VERSION "1.3"

CM_ "RVC DBC File
Author: Dominique Parolin & Damiano Liviero
for Winnebago Industries Inc.
";

NS_ :

BS_:
BU_:

BO_ 2382359889 LEVELING_CONTROL_STATUS: 8 Vector__XXX
    SG_ Operating_Mode        :   0|8@1+      (1,0)   [0|255]   "A"     Vector__XXX
    SG_ Auto_Jack_Status        :   8|2@1+      (1,0)   [0|3]     "A"     Vector__XXX
    SG_ Air_Level_Sleep_Mode        :   10|2@1+     (1,0)   [0|3]     "A"     Vector__XXX
    SG_ Air_Releveling_Mode        :   12|2@1+     (1,0)   [0|3]     "A"     Vector__XXX
    SG_ Excessive_Slope_Initial_Warning        :   16|2@1+     (1,0)   [0|3]     "A"     Vector__XXX
    SG_ Excessive_Slope_Final_Warning        :   18|2@1+     (1,0)   [0|3]     "A"     Vector__XXX
    SG_ Leveling_System_Master_Warning        :   20|2@1+     (1,0)   [0|3]     "A"     Vector__XXX
    SG_ Jack_Retrack_Left_Rear        :   24|2@1+     (1,0)   [0|3]     "A"     Vector__XXX
    SG_ Jack_Extend_Left_Rear        :   26|2@1+     (1,0)   [0|3]     "A"     Vector__XXX
    SG_ Jack_Retrack_Right_Front        :   28|2@1+     (1,0)   [0|3]     "A"     Vector__XXX
    SG_ Jack_Extend_Right_Front        :   30|2@1+     (1,0)   [0|3]     "A"     Vector__XXX
    SG_ Jack_Retrack_Right_Rear        :   32|2@1+     (1,0)   [0|3]     "A"     Vector__XXX
    SG_ Jack_Extend_Right_Rear        :   34|2@1+     (1,0)   [0|3]     "A"     Vector__XXX
    SG_ Jack_Retrack_Left_Front        :   36|2@1+     (1,0)   [0|3]     "A"     Vector__XXX
    SG_ Jack_Extend_Left_Front        :   38|2@1+     (1,0)   [0|3]     "A"     Vector__XXX
    SG_ Jack_Retrack_Tongue        :   48|2@1+     (1,0)   [0|3]     "A"     Vector__XXX
    SG_ Jack_Extend_Tongue        :   50|2@1+     (1,0)   [0|3]     "A"     Vector__XXX
    SG_ Park_Brake        :   56|2@1+     (1,0)   [0|3]     "A"     Vector__XXX
    SG_ Ignition_Key        :   58|2@1+     (1,0)   [0|3]     "A"     Vector__XXX
    SG_ Low_Voltage        :   60|2@1+     (1,0)   [0|3]     "A"     Vector__XXX
    SG_ Other_Lockout        :   62|2@1+     (1,0)   [0|3]     "A"     Vector__XXX

    0 "Leveling system may operate"
    1 "Leveling system may not operate because of Park Brake status"
    3 "Unavailable";

    0 "Leveling system may operate"
    1 "Leveling system may not operate because of Ignition status"
    3 "Unavailable";

    0 "Leveling system may operate"
    1 "Leveling system may not operate because of Low Voltage status"
    3 "Unavailable";

    0 "Leveling system may operate"
    1 "Leveling system may not operate because of an additional lockout"
    3 "Unavailable";

    0 "Inactive"
    3 "Store Active"
    72 "Manual Hydraulic leveling - Biax mode"
    82 "Automatic Hydraulic leveling - Biax mode";

BO_ 2180958720 DM_RV: 8 Vector__XXX
    SG_ Operating_Status_1:        0|2@1+      (1,0)   [0|2]   "A"     Vector__XXX
    SG_ Operating_Status_2:        2|2@1+      (1,0)   [0|2]   "A"     Vector__XXX
    SG_ Yellow_Lamp_Status:        4|2@1+      (1,0)   [0|2]   "A"     Vector__XXX
    SG_ Red_Lamp_Status:        6|2@1+      (1,0)   [0|2]   "A"     Vector__XXX
    SG_ DSA:        8|8@1+      (1,0)   [0|255]   "A"     Vector__XXX
    SG_ SPN_MSB:        16|8@1+      (1,0)   [0|255]   "A"     Vector__XXX
    SG_ SPN_ISB:        24|8@1+      (1,0)   [0|255]   "A"     Vector__XXX
    SG_ FMI:        32|5@1+      (1,0)   [0|255]   "A"     Vector__XXX
    SG_ SPN_LSB:        37|3@1+      (1,0)   [0|255]   "A"     Vector__XXX

    0   "Reserved"
    63  "Reserved"
    64  "Generator"
    65  "Genstart Controller"
    66  "Inverter #1"
    67  "Inverter #2"
    68  "Control Panel"
    69  "Battery State of Charge Monitor"
    70  "Battery"

    73  "LPG Tank System"

    77  "AC Load Monitor / Controller"

    81  "Hydraulic/Electric Leveling System Controller"

    88  "Main Thermostat"

    94  "Main Furnace (Conventional)"

    101 "Water Heater #1"
    102 "Water Heater #2"
    103 "Air Conditioner #1"
    104 "Air Conditioner #2"
    105 "Air Conditioner #3"
    106 "Air Conditioner #4"

    132 "DC Input, Keypad"

    141 "Solar Charge Controller"
    142 "Roof Fan"

    144 "Generic Alarm"

    249 "Service Tool"
    250 "System Clock"

    252 "Chassis Bridge"

    255 "Data Invalid";

    0	"Datum value above normal range"
    1	"Datum value below normal range"
    2	"Datum value erratic or invalid"
    3	"Short circuit to high voltage (or complete sensor input failure)"
    4	"Short circuit to low voltage (or complete sensor input failure) "
    5	"Open circuit, or output current below normal"
    6	"Grounded circuit, or output current above normal"
    7	"Mechanical device not responding"
    8	"Datum value showing error of frequency, pulse width, or period"
    9	"Datum not updating at proper rate"
    10	"Datum value fluctuating at abnormal rate"
    11	"Failure not identifiable"
    12	"Bad intelligent RV-C node"
    13	"Calibration required"
    14	"None of the above"
    15	"Datum valid but above normal operational range (least severe) "
    16	"Datum valid but above normal operational range (moderately severe) "
    17	"Datum valid but below normal operational range (least severe) "
    18	"Datum valid but below normal operational range (moderately severe) "
    19	"Received invalid network datum "
    20	"Network Device Not Responding "
    21	"Networked Device Not Responding (failure due to the unresponsiveness of a second networked device) "
    22	"Reverse polarity "
    23	"Reserved"
    24	"Reserved"
    25	"Reserved"
    26	"Reserved"
    27	"Reserved"
    28	"Reserved"
    29	"Reserved"
    30	"Reserved"
    31	"Failure mode not available";

    0 "Specific Point Unknown"
    1 "Node Microprocessor (or ECM)"
    2 "Node Analog-Digital Converter"
    3 "Node Settings or Configuration"
    4 "Node RAM"
    5 "Node Power Supply"
    6 "Node Temperature"
    7 "Node Clock / Timer"
    8 "Node Date / Time. Usually indicates a product that requires a clock DGN from another source."
    9 "Node RV-C Connection. Usually indicates a product that requires a specific DGN from another source."
    10 "Node Serial/ID Number"
    11 "Node Processor Supervisor (Watchdog)"
    12 "Node Firmware"
    13 "Node Internal Subnetwork Communications.";

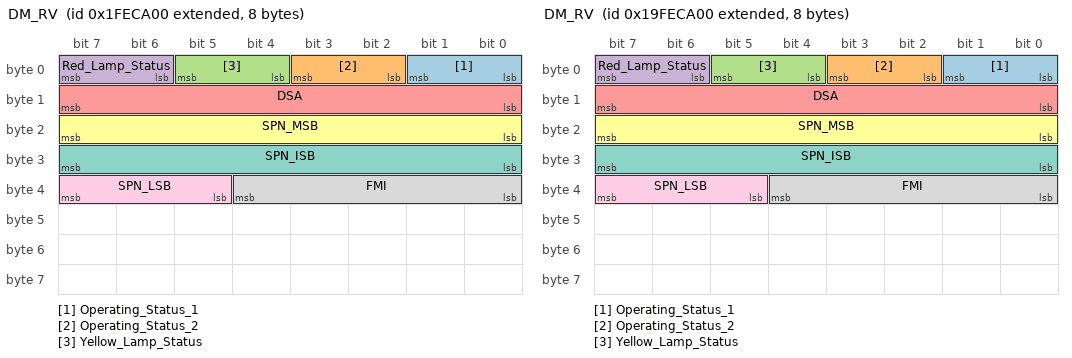
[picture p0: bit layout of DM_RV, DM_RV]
BO_ 2583611904 DM_RV: 8 Vector__XXX
    SG_ Operating_Status_1:        0|2@1+      (1,0)   [0|2]   "A"     Vector__XXX
    SG_ Operating_Status_2:        2|2@1+      (1,0)   [0|2]   "A"     Vector__XXX
    SG_ Yellow_Lamp_Status:        4|2@1+      (1,0)   [0|2]   "A"     Vector__XXX
    SG_ Red_Lamp_Status:        6|2@1+      (1,0)   [0|2]   "A"     Vector__XXX
    SG_ DSA:        8|8@1+      (1,0)   [0|255]   "A"     Vector__XXX
    SG_ SPN_MSB:        16|8@1+      (1,0)   [0|255]   "A"     Vector__XXX
    SG_ SPN_ISB:        24|8@1+      (1,0)   [0|255]   "A"     Vector__XXX
    SG_ FMI:        32|5@1+      (1,0)   [0|255]   "A"     Vector__XXX
    SG_ SPN_LSB:        37|3@1+      (1,0)   [0|255]   "A"     Vector__XXX

    0   "Reserved"
    63  "Reserved"
    64  "Generator"
    65  "Genstart Controller"
    66  "Inverter #1"
    67  "Inverter #2"
    68  "Control Panel"
    69  "Battery State of Charge Monitor"
    70  "Battery"

    73  "LPG Tank System"

    77  "AC Load Monitor / Controller"

    81  "Hydraulic/Electric Leveling System Controller"

    88  "Main Thermostat"

    94  "Main Furnace (Conventional)"

    101 "Water Heater #1"
    102 "Water Heater #2"
    103 "Air Conditioner #1"
    104 "Air Conditioner #2"
    105 "Air Conditioner #3"
    106 "Air Conditioner #4"

    132 "DC Input, Keypad"

    141 "Solar Charge Controller"
    142 "Roof Fan"

    144 "Generic Alarm"

    249 "Service Tool"
    250 "System Clock"

    252 "Chassis Bridge"

    255 "Data Invalid";

    0	"Datum value above normal range"
    1	"Datum value below normal range"
    2	"Datum value erratic or invalid"
    3	"Short circuit to high voltage (or complete sensor input failure)"
    4	"Short circuit to low voltage (or complete sensor input failure) "
    5	"Open circuit, or output current below normal"
    6	"Grounded circuit, or output current above normal"
    7	"Mechanical device not responding"
    8	"Datum value showing error of frequency, pulse width, or period"
    9	"Datum not updating at proper rate"
    10	"Datum value fluctuating at abnormal rate"
    11	"Failure not identifiable"
    12	"Bad intelligent RV-C node"
    13	"Calibration required"
    14	"None of the above"
    15	"Datum valid but above normal operational range (least severe) "
    16	"Datum valid but above normal operational range (moderately severe) "
    17	"Datum valid but below normal operational range (least severe) "
    18	"Datum valid but below normal operational range (moderately severe) "
    19	"Received invalid network datum "
    20	"Network Device Not Responding "
    21	"Networked Device Not Responding (failure due to the unresponsiveness of a second networked device) "
    22	"Reverse polarity "
    23	"Reserved"
    24	"Reserved"
    25	"Reserved"
    26	"Reserved"
    27	"Reserved"
    28	"Reserved"
    29	"Reserved"
    30	"Reserved"
    31	"Failure mode not available";

    0 "Specific Point Unknown"
    1 "Node Microprocessor (or ECM)"
    2 "Node Analog-Digital Converter"
    3 "Node Settings or Configuration"
    4 "Node RAM"
    5 "Node Power Supply"
    6 "Node Temperature"
    7 "Node Clock / Timer"
    8 "Node Date / Time. Usually indicates a product that requires a clock DGN from another source."
    9 "Node RV-C Connection. Usually indicates a product that requires a specific DGN from another source."
    10 "Node Serial/ID Number"
    11 "Node Processor Supervisor (Watchdog)"
    12 "Node Firmware"
    13 "Node Internal Subnetwork Communications.";

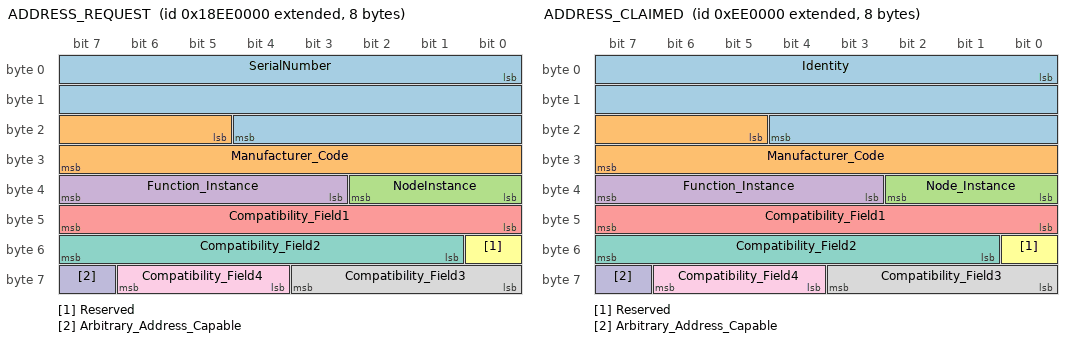
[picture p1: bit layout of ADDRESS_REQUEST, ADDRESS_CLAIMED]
BO_ 2565734400 ADDRESS_REQUEST: 8 Vector__XXX
    SG_ SerialNumber:        0|21@1+      (1,0)   [0|2097151]     "A"     Vector__XXX
    SG_ Manufacturer_Code:        21|11@1+     (1,0)   [0|100000]      "A"     Vector__XXX
    SG_ NodeInstance:        32|3@1+ (1,0) [0|7] "A" Vector__XXX
    SG_ Function_Instance:        35|5@1+ (1,0) [0|31] "A" Vector__XXX
    SG_ Compatibility_Field1:        40|8@1+ (1,0) [0|255] "A" Vector__XXX
    SG_ Reserved:        48|1@1+ (1,0) [0|1] "A" Vector__XXX
    SG_ Compatibility_Field2:        49|7@1+ (1,0) [0|127] "A" Vector__XXX
    SG_ Compatibility_Field3:        56|4@1+ (1,0) [0|15] "A" Vector__XXX
    SG_ Compatibility_Field4:        60|3@1+ (1,0) [0|7] "A" Vector__XXX
    SG_ Arbitrary_Address_Capable:        63|1@1+ (1,0) [0|1] "A" Vector__XXX

    0 "Node uses a fixed source address"
    1 "Node supports address claiming";

    101	"Atwood Mobile Products"
    102	"Carefree of Colorado"
    103	"Dometic Corporation"
    104	"Freightliner Custom Chassis Corp."
    105	"General Dynamics - Intellitec Products"
    106	"Girard Systems"
    107	"Hopkins Manufacturing Corp."
    108	"HWH Corporation"
    109	"Integrated Power Systems"
    110	"Onan / Cummins Power Generation"
    111	"Progressive Dynamics, Inc."
    112	"SilverLeaf Electronics, Inc."
    113	"Spartan Motors Chassis, Inc."
    114	"Technology Research Corporation"
    115	"Transportation Systems Design, Inc."
    116	"Vehicle Systems, Inc."
    117	"Wire Design, Inc."
    118	"Workhorse Custom Chassis"
    119	"Xantrex Technology, Inc."
    120	"Power Gear"
    121	"RV Products"
    122	"Suburban"
    123	"Borg-Warner"
    124	"Garnet Instruments"
    125	"American Technology"
    126	"Automated Engineering Corp.";

BO_ 2163081216 ADDRESS_CLAIMED: 8 Vector__XXX
    SG_ Identity:        0|21@1+      (1,0)   [0|2097151]     "A"     Vector__XXX
    SG_ Manufacturer_Code:        21|11@1+     (1,0)   [0|100000]      "A"     Vector__XXX
    SG_ Node_Instance:        32|3@1+ (1,0) [0|7] "A" Vector__XXX
    SG_ Function_Instance:        35|5@1+ (1,0) [0|31] "A" Vector__XXX
    SG_ Compatibility_Field1:        40|8@1+ (1,0) [0|255] "A" Vector__XXX
    SG_ Reserved:        48|1@1+ (1,0) [0|1] "A" Vector__XXX
    SG_ Compatibility_Field2:        49|7@1+ (1,0) [0|127] "A" Vector__XXX
    SG_ Compatibility_Field3:        56|4@1+ (1,0) [0|15] "A" Vector__XXX
    SG_ Compatibility_Field4:        60|3@1+ (1,0) [0|7] "A" Vector__XXX
    SG_ Arbitrary_Address_Capable:        63|1@1+ (1,0) [0|1] "A" Vector__XXX

    0 "Node uses a fixed source address"
    1 "Node supports address claiming";

    101	"Atwood Mobile Products"
    102	"Carefree of Colorado"
    103	"Dometic Corporation"
    104	"Freightliner Custom Chassis Corp."
    105	"General Dynamics - Intellitec Products"
    106	"Girard Systems"
    107	"Hopkins Manufacturing Corp."
    108	"HWH Corporation"
    109	"Integrated Power Systems"
    110	"Onan / Cummins Power Generation"
    111	"Progressive Dynamics, Inc."
    112	"SilverLeaf Electronics, Inc."
    113	"Spartan Motors Chassis, Inc."
    114	"Technology Research Corporation"
    115	"Transportation Systems Design, Inc."
    116	"Vehicle Systems, Inc."
    117	"Wire Design, Inc."
    118	"Workhorse Custom Chassis"
    119	"Xantrex Technology, Inc."
    120	"Power Gear"
    121	"RV Products"
    122	"Suburban"
    123	"Borg-Warner"
    124	"Garnet Instruments"
    125	"American Technology"
    126	"Automated Engineering Corp.";

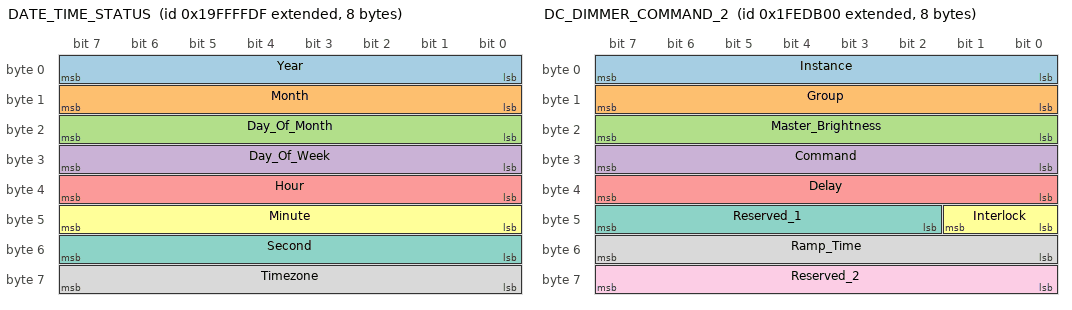
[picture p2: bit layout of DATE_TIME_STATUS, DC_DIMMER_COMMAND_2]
BO_ 2583691231 DATE_TIME_STATUS: 8 Vector__XXX
    SG_ Year:        0|8@1+  (1,2000)   [0|250]     "Year"  Vector__XXX
    SG_ Month:        8|8@1+  (1,0)   [1|12]     "Month"  Vector__XXX
    SG_ Day_Of_Month:        16|8@1+    (1,0)    [0|31]   "Day Number"     Vector__XXX
    SG_ Day_Of_Week:        24|8@1+    (1,0)   [1|7]   "Day Name"     Vector__XXX
    SG_ Hour:        32|8@1+    (1,0)   [0|23]   "h"     Vector__XXX
    SG_ Minute:        40|8@1+    (1,0)   [0|59]   "min"     Vector__XXX
    SG_ Second:        48|8@1+    (1,0)   [0|59]   "s"     Vector__XXX
    SG_ Timezone:        56|8@1+    (1,0)   [0|255]   "h"     Vector__XXX

    0 "Invalid"
    1 "Sunday"
    2 "Monday"
    3 "Tuesday"
    4 "Wednesday"
    5 "Thursday"
    6 "Friday"
    7 "Saturday"
    255 "Not supported";

    0 "Greenwich Mean Time"
    4 "Eastern Daylight Time"
    5 "Eastern Standard Time"
    7 "Pacific Daylight Time"
    8 "Pacific Standard Time"
    0 "Western European Time"
    22 "Central European Summer Time"
    255 "Not supported";

BO_ 2583615167 MFG_SPECIFIC_CLAIM_REQUEST: 8 Vector__XXX
    SG_ Manufacturer_Code_MSB:        0|16@1+     (1,0)   [0|100000]      "A"     Vector__XXX

    101	"Atwood Mobile Products"
    102	"Carefree of Colorado"
    103	"Dometic Corporation"
    104	"Freightliner Custom Chassis Corp."
    105	"General Dynamics - Intellitec Products"
    106	"Girard Systems"
    107	"Hopkins Manufacturing Corp."
    108	"HWH Corporation"
    109	"Integrated Power Systems"
    110	"Onan / Cummins Power Generation"
    111	"Progressive Dynamics, Inc."
    112	"SilverLeaf Electronics, Inc."
    113	"Spartan Motors Chassis, Inc."
    114	"Technology Research Corporation"
    115	"Transportation Systems Design, Inc."
    116	"Vehicle Systems, Inc."
    117	"Wire Design, Inc."
    118	"Workhorse Custom Chassis"
    119	"Xantrex Technology, Inc."
    120	"Power Gear"
    121	"RV Products"
    122	"Suburban"
    123	"Borg-Warner"
    124	"Garnet Instruments"
    125	"American Technology"
    126	"Automated Engineering Corp.";

BO_ 2180963072 DC_DIMMER_COMMAND_2: 8 Vector__XXX
    SG_ Instance:        0|8@1+ (1,0) [1|255] "Instance" Vector__XXX
    SG_ Group:        8|8@1+ (1,0) [129|255] "Group" Vector__XXX
    SG_ Master_Brightness:        16|8@1+ (0.5,0) [0|200] "%" Vector__XXX
    SG_ Command:        24|8@1+ (1,0) [0|255] "Cmd" Vector__XXX
    SG_ Delay:        32|8@1+ (1,0) [0|255] "Sec/Min" Vector__XXX
    SG_ Interlock:        40|2@1+ (1,0) [0|255] "" Vector__XXX
    SG_ Reserved_1:        42|6@1+ (1,0) [0|255] "" Vector__XXX
    SG_ Ramp_Time:        48|8@1+ (1,0) [0|255] "" Vector__XXX
    SG_ Reserved_2:        56|8@1+ (1,0) [0|255] "" Vector__XXX

    255 "Group Command";

    129 "Node Group 1"
    130 "Node Group 2"
    131 "Node Group 3"
    132 "Node Group 4"
    133 "Node Group 5"
    134 "Node Group 6"
    135 "Node Group 7"
    136 "Node Group 8"
    255 "Non-group command";

    230 "Scene 1 Memory Value"
    231 "Scene 2 Memory Value"
    232 "Scene 3 Memory Value"
    233 "Scene 4 Memory Value"
    234 "Scene 5 Memory Value"
    235 "Scene 6 Memory Value"
    236 "Scene 7 Memory Value"
    237 "Scene 8 Memory Value"
    238 "Scene 9 Memory Value"
    239 "Scene 10 Memory Value"
    240 "Scene 11 Memory Value"
    249 "Scene 20 Memory Value"
    250 "selects the Dimmed Memory Value"
    251 "selects the Master Memory Value";

CM_" Need to update stuff below for RVC";

    0 "Set Level Direct"
    1 "ON - 100% direct"
    2 "ON - Delay"
    3 "OFF"
    4 "Stop Ramping"
    5 "Toggle between 0% and 100% and vice versa"

    8 "Switch Poke"
    9 "Switch Press and hold"
    10 "Switch Release"

    19 "Ramp Up from current brightness to 100%"
    20 "Ramp down from current brightness to 0%";

    241 "5 min"
    242 "6 min"
    243 "7 min"
    244 "8 min"
    245 "9 min"
    246 "10 min"
    247 "11 min"
    248 "12 min"
    249 "13 min"
    250 "14 min"
    255 "Continuous/NA";

    0 "No interlock active"
    1 "Interlock A"
    2 "Interlock B"
    3 "NA";

    63 "NA";

    255 "NA";

    255 "NA";

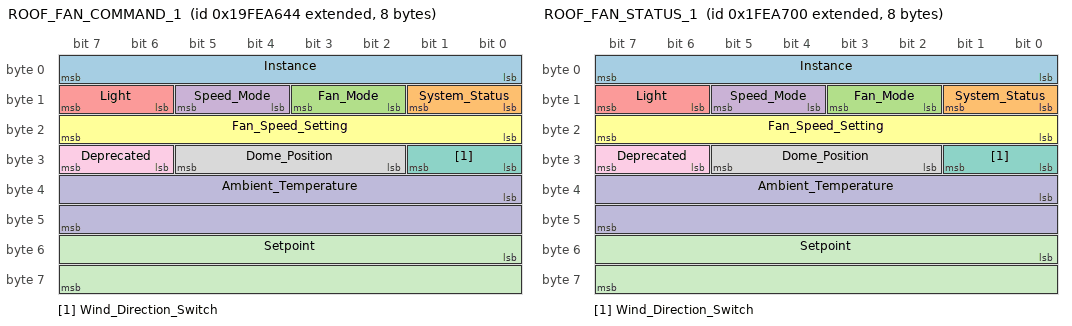
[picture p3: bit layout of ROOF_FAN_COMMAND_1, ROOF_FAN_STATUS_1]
BO_ 2583602756 ROOF_FAN_COMMAND_1: 8   Vector__XXX
    SG_ Instance:        0|8@1+ (1,0) [0|255] "Instance" Vector__XXX
    SG_ System_Status:        8|2@1+  (1,0)   [0|15]  "onOff"  Vector__XXX
    SG_ Fan_Mode:        10|2@1+ (1,0)   [0|3]   "Mode"  Vector__XXX
    SG_ Speed_Mode:        12|2@1+ (1,0)   [0|3]   "Mode"  Vector__XXX
    SG_ Light:        14|2@1+ (1,0)   [0|1]   "onOff" Vector__XXX
    SG_ Fan_Speed_Setting:        16|8@1+ (0.5,0)   [0|255] "%" Vector__XXX
    SG_ Wind_Direction_Switch:        24|2@1+ (1,0)   [0|3]   ""  Vector__XXX
    SG_ Dome_Position:        26|4@1+ (1,0)   [0|15]  ""  Vector__XXX
    SG_ Deprecated:        30|2@1+ (1,0)   [0|15]  ""  Vector__XXX
    SG_ Ambient_Temperature:        32|16@1+    (0.03125,-273) [-273|1735] "deg C" Vector__XXX
    SG_ Setpoint:        48|16@1+    (0.03125,-273) [-273|1735] "deg C" Vector__XXX

    0 "Off"
    1 "On";

    0 "Auto"
    1 "Forced On";

    0 "Auto (Variable)"
    1 "Manual";

    0 "Off"
    1 "On";

    0 "Air Out"
    1 "Air In";

    0 "Closed"
    1 "1/4 Open"
    2 "1/2 Open"
    3 "3/4 Open"
    4 "Open";

BO_ 2180949760 ROOF_FAN_STATUS_1: 8   Vector__XXX
    SG_ Instance:        0|8@1+ (1,0) [0|255] "Instance" Vector__XXX
    SG_ System_Status:        8|2@1+  (1,0)   [0|15]  "onOff"  Vector__XXX
    SG_ Fan_Mode:        10|2@1+ (1,0)   [0|3]   "Mode"  Vector__XXX
    SG_ Speed_Mode:        12|2@1+ (1,0)   [0|3]   "Mode"  Vector__XXX
    SG_ Light:        14|2@1+ (1,0)   [0|1]   "onOff" Vector__XXX
    SG_ Fan_Speed_Setting:        16|8@1+ (0.5,0)   [0|255] "%" Vector__XXX
    SG_ Wind_Direction_Switch:        24|2@1+ (1,0)   [0|3]   ""  Vector__XXX
    SG_ Dome_Position:        26|4@1+ (1,0)   [0|15]  ""  Vector__XXX
    SG_ Deprecated:        30|2@1+ (1,0)   [0|15]  ""  Vector__XXX
    SG_ Ambient_Temperature:        32|16@1+    (0.03125,-273) [-273|1735] "deg C" Vector__XXX
    SG_ Setpoint:        48|16@1+    (0.03125,-273) [-273|1735] "deg C" Vector__XXX

    0 "Off"
    1 "On";

    0 "Auto"
    1 "Forced On";

    0 "Auto (Variable)"
    1 "Manual";

    0 "Off"
    1 "On";

    0 "Air Out"
    1 "Air In";

    0 "Closed"
    1 "1/4 Open"
    2 "1/2 Open"
    3 "3/4 Open"
    4 "Open";

CM_ "1FF9C";
BO_ 2181012480 THERMOSTAT_AMBIENT_STATUS: 8  Vector__XXX
    SG_ Instance:        0|8@1+  (1,0)   [0|255] ""    Vector__XXX
    SG_ Ambient_Temp:        8|16@1+  (0.03125,-273) [-8736|56799] "deg C"    Vector__XXX

    65535 "Data Invalid";

CM_ "1FEF7";
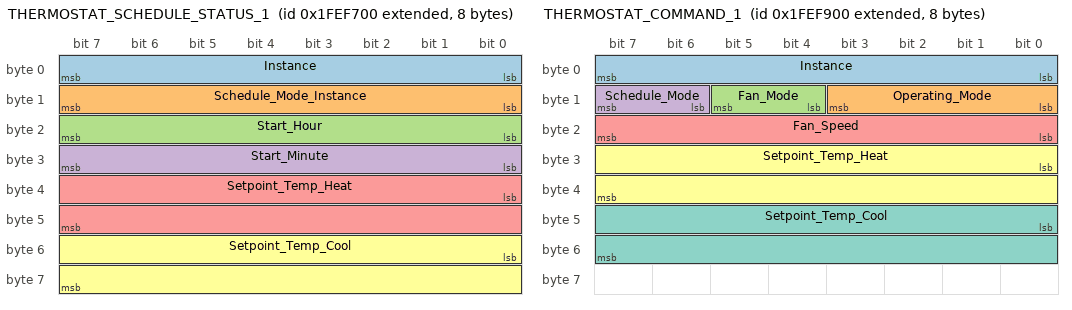
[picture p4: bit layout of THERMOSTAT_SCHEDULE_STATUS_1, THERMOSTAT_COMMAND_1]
BO_ 2180970240 THERMOSTAT_SCHEDULE_STATUS_1: 8  Vector__XXX
    SG_ Instance:        0|8@1+  (1,0)   [0|255] ""    Vector__XXX
    SG_ Schedule_Mode_Instance:        8|8@1+  (1,0)   [0|255] ""    Vector__XXX
    SG_ Start_Hour:        16|8@1+  (1,0)   [0|255] "hr"    Vector__XXX
    SG_ Start_Minute:        24|8@1+  (1,0)   [0|255] "min"    Vector__XXX
    SG_ Setpoint_Temp_Heat:        32|16@1+  (0.03125,-273) [-8736|56799] "deg C"    Vector__XXX
    SG_ Setpoint_Temp_Cool:        48|16@1+  (0.03125,-273) [-8736|56799] "deg C"    Vector__XXX

    0 "Sleep"
    1 "Wake"
    2 "Away"
    3 "Return"
    250 "Storage"
    255 "Data invalid";

    0 "12:00 AM"
    12 "12:00 Noon"
    23 "11:00 PM"
    255 "Data invalid";

CM_ "1FEF9";
BO_ 2180970752 THERMOSTAT_COMMAND_1: 8  Vector__XXX
    SG_ Instance:        0|8@1+  (1,0)   [0|255] ""    Vector__XXX
    SG_ Operating_Mode:        8|4@1+  (1,0)   [0|15] ""    Vector__XXX
    SG_ Fan_Mode:        12|2@1+  (1,0)   [0|3] ""    Vector__XXX
    SG_ Schedule_Mode:        14|2@1+  (1,0)   [0|3] ""    Vector__XXX
    SG_ Fan_Speed:        16|8@1+  (0.5,0)   [0|255] "%"    Vector__XXX
    SG_ Setpoint_Temp_Heat:        24|16@1+  (0.03125,-273) [-8736|56799] "deg C"    Vector__XXX
    SG_ Setpoint_Temp_Cool:        40|16@1+  (0.03125,-273) [-8736|56799] "deg C"    Vector__XXX

    0 "Off"
    1 "Cool"
    2 "Heat"
    3 "Auto Heat/Cool"
    4 "Fan Only"
    5 "Aux Heat"
    15 "No Data";

    0 "Auto"
    1 "On"
    3 "No Data";

    0 "Disabled"
    1 "Enabled"
    3 "No Data";

    65535 "No Data";

    65535 "No Data";

CM_ "1FFE2";
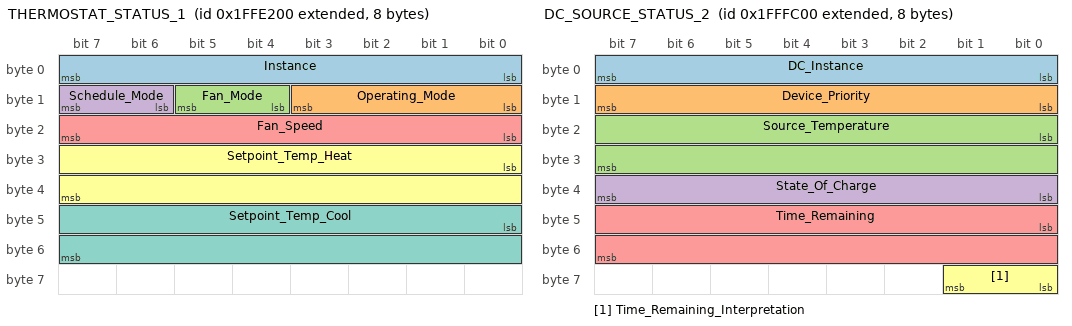
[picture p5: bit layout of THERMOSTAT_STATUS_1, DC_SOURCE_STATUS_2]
BO_ 2181030400 THERMOSTAT_STATUS_1: 8  Vector__XXX
    SG_ Instance:        0|8@1+  (1,0)   [0|255] ""    Vector__XXX
    SG_ Operating_Mode:        8|4@1+  (1,0)   [0|15] ""    Vector__XXX
    SG_ Fan_Mode:        12|2@1+  (1,0)   [0|3] ""    Vector__XXX
    SG_ Schedule_Mode:        14|2@1+  (1,0)   [0|3] ""    Vector__XXX
    SG_ Fan_Speed:        16|8@1+  (0.5,0)   [0|255] "%"    Vector__XXX
    SG_ Setpoint_Temp_Heat:        24|16@1+  (0.03125,-273) [-8736|56799] "deg C"    Vector__XXX
    SG_ Setpoint_Temp_Cool:        40|16@1+  (0.03125,-273) [-8736|56799] "deg C"    Vector__XXX

    0 "Off"
    1 "Cool"
    2 "Heat"
    3 "Auto heat/Cool"
    4 "Fan only"
    5 "Aux Heat"
    15 "Data invalid";

    0 "Auto"
    1 "On"
    3 "Data invalid";

    0 "Disabled"
    1 "Enabled"
    3 "Data invalid";

CM_ "1FEFA";
BO_ 2180971008 THERMOSTAT_STATUS_2: 8  Vector__XXX
    SG_ Instance:        0|8@1+  (1,0)   [0|255] ""    Vector__XXX
    SG_ Current_Schedule_Instance:        8|8@1+  (1,0)   [0|255] ""    Vector__XXX
    SG_ Number_Of_Schedule_Instances:        16|8@1+  (1,0)   [0|255] ""    Vector__XXX

BO_ 2181019392  TANK_STATUS: 8  Vector__XXX
    SG_ Instance:        0|8@1+  (1,0)   [0|255] "Instance"  Vector__XXX
    SG_ Relative_Level:        8|8@1+  (1,0)   [0|255] "Level" Vector__XXX
    SG_ Resolution:        16|8@1+ (1,0)   [0|255] "Resolution"    Vector__XXX
    SG_ Absolute_Level:        24|16@1+    (1,0)   [0|65530]   "Liter" Vector__XXX
    SG_ Tank_Size:        40|16@1+    (1,0)   [0|65530]   "Liter" Vector__XXX

    0 "Fresh Water"
    1 "Black Waste"
    2 "Grey Waste"
    3 "LPG"
    16 "Second Fresh Water"
    17 "Second Black Waste"
    18 "Second Grey Waste"
    19 "Second LPG";

CM_ "Inverter Start";
CM_ "1FFFD";
BO_ 2181037312 DC_SOURCE_STATUS_1: 8 Vector__XXX
    SG_ Instance:        0|8@1+  (1,0)   [0|255]     ""  Vector__XXX
    SG_ Device_Priority:        8|8@1+  (1,0)   [0|255]     ""  Vector__XXX
    SG_ DC_Voltage:        16|16@1+    (0.05,0)    [0|65535]   "V"     Vector__XXX
    SG_ DC_Current:        32|32@1+    (0.001,-2000000)   [-2000000000|2294967295]   "A"     Vector__XXX

    0 "Invalid"
    1 "Main House Battery Bank"
    2 "Chassis Start Battery"
    3 "Secondary House Battery Bank"
    4 "Generator Starter Battery"
    5 "Arbitrary";

    120 "Battery SOC/BMS device"
    100 "Inverter/Charger"
    80 "Charger"
    60 "Inverter"
    40 "Voltmeter/Ammeter"
    20 "Voltmeter"
    0 "No priority, always reporting";

    65535 "Data Invalid";

    4294967295 "Data Invalid";

CM_ "1FFFC";
BO_ 2181037056 DC_SOURCE_STATUS_2: 8 Vector__XXX
    SG_ DC_Instance:        0|8@1+  (1,0)   [0|255]     ""  Vector__XXX
    SG_ Device_Priority:        8|8@1+  (1,0)   [0|255]     ""  Vector__XXX
    SG_ Source_Temperature:        16|16@1+  (0.03125,-273) [-8736|56799] "deg C"    Vector__XXX
    SG_ State_Of_Charge:        32|8@1+    (0.5,0)   [0|255]   "%"     Vector__XXX
    SG_ Time_Remaining:        40|16@1+    (1,0)   [0|65535]   "Min"     Vector__XXX
    SG_ Time_Remaining_Interpretation:        56|2@1+     (1,0)   [0|3]   ""    Vector__XXX

    0 "Invalid"
    1 "Main House Battery Bank"
    2 "Chassis Start Battery"
    3 "Secondary House Battery Bank"
    4 "Generator Starter Battery"
    5 "Arbitrary"
    255 "Data Invalid";

    120 "Battery SOC/BMS device"
    100 "Inverter/Charger"
    80 "Charger"
    60 "Inverter"
    40 "Voltmeter/Ammeter"
    20 "Voltmeter"
    0 "No priority, always reporting";

    65535 "Data Invalid";

    65535 "Data Invalid";

    0 "Time to Empty"
    1 "Time to Full"
    3 "NA - Implicit time to empty";

CM_ "1FFFB";
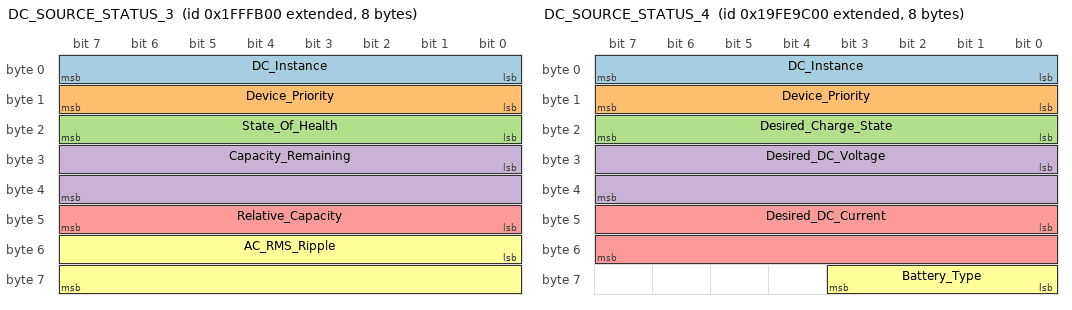
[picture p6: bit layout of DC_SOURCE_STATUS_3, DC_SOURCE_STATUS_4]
BO_ 2181036800 DC_SOURCE_STATUS_3: 8 Vector__XXX
    SG_ DC_Instance:        0|8@1+      (1,0)   [0|255]     ""      Vector__XXX
    SG_ Device_Priority:        8|8@1+      (1,0)   [0|255]     ""      Vector__XXX
    SG_ State_Of_Health:        16|8@1+     (1,0)   [0|255]     "%"     Vector__XXX
    SG_ Capacity_Remaining:        24|16@1+    (1,0)   [0|65530]   "AH"    Vector__XXX
    SG_ Relative_Capacity:        40|8@1+     (1,0)   [0|255]     "%"     Vector__XXX
    SG_ AC_RMS_Ripple:        48|16@1+    (1,0)   [0|65535]   "mV"    Vector__XXX

    0 "Invalid"
    1 "Main House Battery Bank"
    2 "Chassis Start Battery"
    3 "Secondary House Battery Bank"
    4 "Generator Starter Battery"
    5 "Arbitrary"
    255 "Data Invalid";

    120 "Battery SOC/BMS device"
    100 "Inverter/Charger"
    80 "Charger"
    60 "Inverter"
    40 "Voltmeter/Ammeter"
    20 "Voltmeter"
    0 "No priority, always reporting";

    65535 "Data Invalid";

    65535 "Data Invalid";

CM_ "1FE9C";
BO_ 2583600128 DC_SOURCE_STATUS_4: 8 Vector__XXX
    SG_ DC_Instance:                0|8@1+  (1,0)   [0|255]     ""  Vector__XXX
    SG_ Device_Priority:            8|8@1+  (1,0)   [0|255]     ""  Vector__XXX
    SG_ Desired_Charge_State:       16|8@1+  (0.03125,-273) [-8736|56799] "deg C"    Vector__XXX
    SG_ Desired_DC_Voltage:         24|16@1+    (0.5,0)   [0|255]   "%"     Vector__XXX
    SG_ Desired_DC_Current:         40|16@1+    (1,0)   [0|65535]   "Min"     Vector__XXX
    SG_ Battery_Type:               56|4@1+     (1,0)   [0|15]   ""    Vector__XXX

    0 "Invalid"
    1 "Main House Battery Bank"
    2 "Chassis Start Battery"
    3 "Secondary House Battery Bank"
    4 "Generator Starter Battery"
    5 "Arbitrary"
    255 "Data Invalid";

    120 "Battery SOC/BMS device"
    100 "Inverter/Charger"
    80 "Charger"
    60 "Inverter"
    40 "Voltmeter/Ammeter"
    20 "Voltmeter"
    0 "No priority, always reporting";

    0 "Flooded"
    1 "Gel"
    2 "AGM"
    3 "LFP"
    255 "Data Invalid";

CM_ "1FEA5";
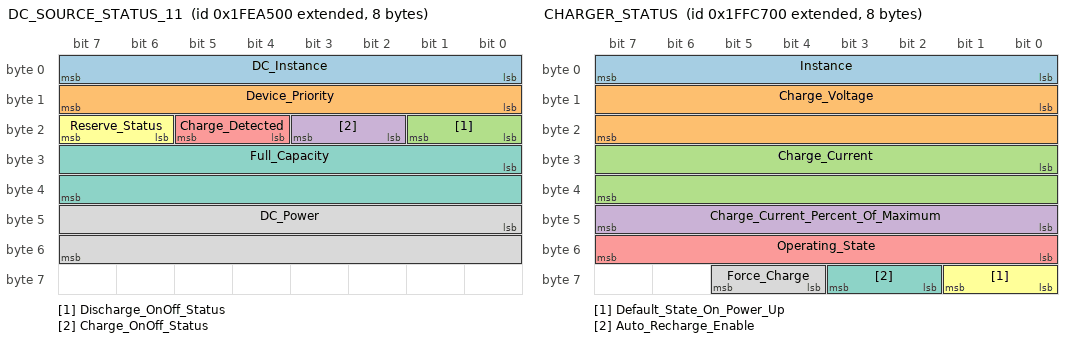
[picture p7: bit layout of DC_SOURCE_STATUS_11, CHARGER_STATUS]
BO_ 2180949248 DC_SOURCE_STATUS_11: 8 Vector__XXX
    SG_ DC_Instance:        0|8@1+      (1,0)   [0|255]     ""      Vector__XXX
    SG_ Device_Priority:        8|8@1+      (1,0)   [0|255]     ""      Vector__XXX
    SG_ Discharge_OnOff_Status:        16|2@1+     (1,0)   [0|255]     ""     Vector__XXX
    SG_ Charge_OnOff_Status:        18|2@1+     (1,0)   [0|255]     ""     Vector__XXX
    SG_ Charge_Detected:        20|2@1+     (1,0)   [0|255]     ""     Vector__XXX
    SG_ Reserve_Status:        22|2@1+     (1,0)   [0|255]     ""     Vector__XXX
    SG_ Full_Capacity:        24|16@1+    (1,0)   [0|65535]   "AH"    Vector__XXX
    SG_ DC_Power:        40|16@1+     (1,0)   [0|65535]  "W"     Vector__XXX

    0 "Invalid"
    1 "Main House Battery Bank"
    2 "Chassis Start Battery"
    3 "Secondary House Battery Bank"
    4 "Generator Starter Battery"
    5 "Arbitrary"
    255 "Data Invalid";

    120 "Battery SOC/BMS device"
    100 "Inverter/Charger"
    80 "Charger"
    60 "Inverter"
    40 "Voltmeter/Ammeter"
    20 "Voltmeter"
    0 "No priority, always reporting";

    65535 "Data Invalid";

    65535 "Data Invalid";

CM_ "1FFD7";
BO_ 2181027584 INVERTER_AC_STATUS_1: 8 Vector__XXX
    SG_ Instance:        0|8@1+  (1,0)   [0|255]     ""  Vector__XXX
    SG_ RMS_Voltage:        8|16@1+  (0.05,0)   [0|65535]     "V"  Vector__XXX
    SG_ RMS_Current:        24|16@1+    (0.05,-1600)   [-32000|33535]   "A"     Vector__XXX
    SG_ Frequency:        40|16@1+    (0.0078125,0)   [0|65535]   "Hz"     Vector__XXX

    65535 "Data Invalid";

    65535 "Data Invalid";

    65535 "Data Invalid";

CM_ "1FFCA";
BO_ 2181024256 CHARGER_AC_STATUS_1: 8 Vector__XXX
    SG_ Instance:        0|8@1+  (1,0)   [0|255]     ""  Vector__XXX
    SG_ RMS_Voltage:        8|16@1+  (0.05,0)   [0|65535]     "V"  Vector__XXX
    SG_ RMS_Current:        24|16@1+    (0.05,-1600)   [-32000|33535]   "A"     Vector__XXX
    SG_ Frequency:        40|16@1+    (0.0078125,0)   [0|65535]   "Hz"     Vector__XXX

    65535 "Data Invalid";

    65535 "Data Invalid";

    65535 "Data Invalid";

CM_ "1FFC9";
BO_ 2181024000 CHARGER_AC_STATUS_2: 8 Vector__XXX
    SG_ Instance:        0|8@1+  (1,0)   [0|255]     ""  Vector__XXX
    SG_ Peak_Voltage:        8|16@1+  (0.05,0)   [0|65535]     "V"  Vector__XXX
    SG_ Peak_Current:        24|16@1+    (0.05,-1600)   [-32000|33535]   "A"     Vector__XXX
    SG_ Ground_Current:        40|16@1+    (0.05,-1600)   [-32000|33535]   "A"     Vector__XXX
    SG_ Capacity:        56|8@1+    (1,0)   [0|255]   "A"     Vector__XXX

    65535 "Data Invalid";

    65535 "Data Invalid";

    65535 "Data Invalid";

CM_ "1FFC7";
BO_ 2181023488 CHARGER_STATUS: 8 Vector__XXX
    SG_ Instance:        0|8@1+  (1,0)   [0|255]     ""  Vector__XXX
    SG_ Charge_Voltage:        8|16@1+  (0.05,0)   [0|65535]     "V"  Vector__XXX
    SG_ Charge_Current:        24|16@1+    (0.05,-1600)   [-32000|33535]   "A"     Vector__XXX
    SG_ Charge_Current_Percent_Of_Maximum:        40|8@1+    (0.5,0)   [0|255]   "%"     Vector__XXX
    SG_ Operating_State:        48|8@1+    (1,0)   [0|255]   ""     Vector__XXX
    SG_ Default_State_On_Power_Up:        56|2@1+    (1,0)   [0|3]   ""     Vector__XXX
    SG_ Auto_Recharge_Enable:        58|2@1+    (1,0)   [0|3]   ""     Vector__XXX
    SG_ Force_Charge:        60|2@1+    (1,0)   [0|3]   ""     Vector__XXX

    65535 "Data Invalid";

    65535 "Data Invalid";

    0 "Disable"
    1 "Not charging"
    2 "Bulk"
    3 "Absorption"
    4 "Overcharge"
    5 "Equalize"
    6 "Float"
    7 "Constant voltage/Current"
    255 "Data Invalid";

    0 "Charger disabled"
    1 "Charger enabled"
    3 "Data Invalid";

    0 "Auto recharge disabled"
    1 "Auto recharge enabled"
    3 "Data Invalid";

    0 "Charging is not forced"
    1 "Force charge to bulk"
    2 "Force charge to float"
    3 "Data Invalid";

CM_ "1FEA3";
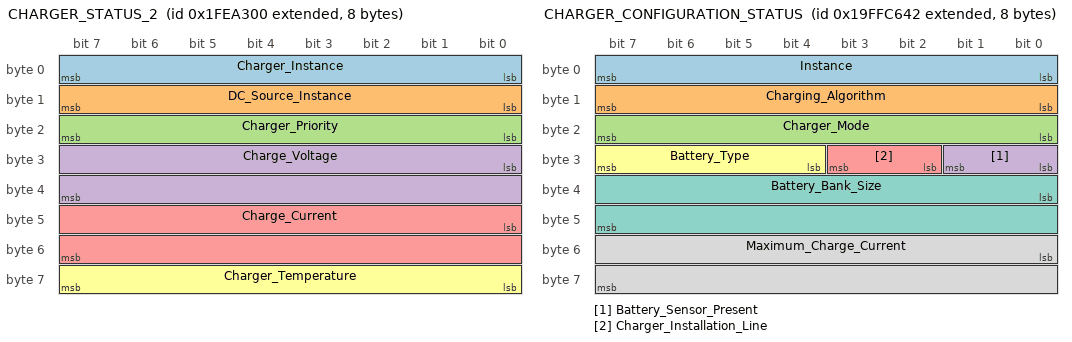
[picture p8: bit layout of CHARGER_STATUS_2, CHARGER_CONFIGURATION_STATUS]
BO_ 2180948736 CHARGER_STATUS_2: 8 Vector__XXX
    SG_ Charger_Instance:        0|8@1+  (1,0)   [0|255]     ""  Vector__XXX
    SG_ DC_Source_Instance:        8|8@1+  (1,0)   [0|255]     ""  Vector__XXX
    SG_ Charger_Priority:        16|8@1+  (1,0)   [0|255]     ""  Vector__XXX
    SG_ Charge_Voltage:        24|16@1+  (0.05,0)   [0|65535]     "V"  Vector__XXX
    SG_ Charge_Current:        40|16@1+    (0.05,-1600)   [-32000|33535]   "A"     Vector__XXX
    SG_ Charger_Temperature:        56|8@1+  (1,-40) [-40|215] "deg C"    Vector__XXX

    65535 "Data Invalid";

    65535 "Data Invalid";

CM_ "1FFC6";
BO_ 2583676482 CHARGER_CONFIGURATION_STATUS: 8 Vector__XXX
    SG_ Instance:        0|8@1+  (1,0)   [0|255]     ""  Vector__XXX
    SG_ Charging_Algorithm:        8|8@1+  (1,0)   [0|255]     ""  Vector__XXX
    SG_ Charger_Mode:        16|8@1+  (1,0)   [0|255]     ""  Vector__XXX
    SG_ Battery_Sensor_Present:        24|2@1+  (1,0)   [0|1]     ""  Vector__XXX
    SG_ Charger_Installation_Line:        26|2@1+  (1,0)   [0|1]     ""  Vector__XXX
    SG_ Battery_Type:        28|4@1+  (1,0)   [0|1]     ""  Vector__XXX
    SG_ Battery_Bank_Size:        32|16@1+  (1,0)   [0|65535]     "Ah"  Vector__XXX
    SG_ Maximum_Charge_Current:        48|16@1+  (0.05,-1600)   [-1600|65535]    "A"  Vector__XXX

CM_ "1FF95";
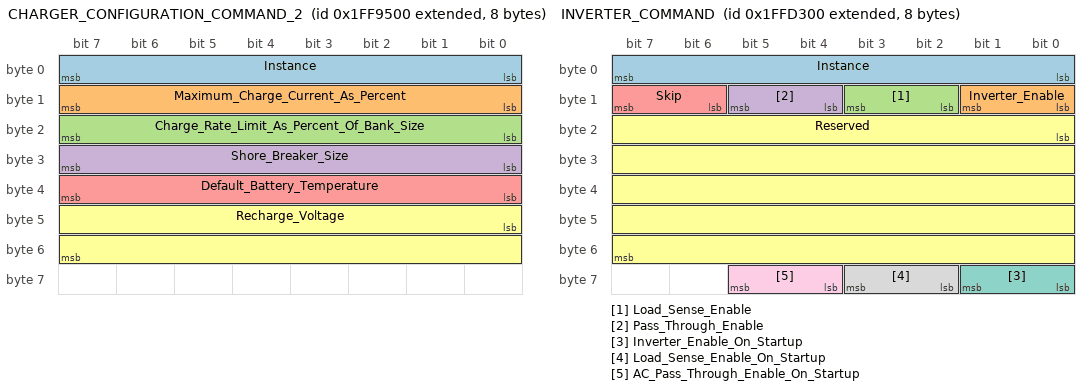
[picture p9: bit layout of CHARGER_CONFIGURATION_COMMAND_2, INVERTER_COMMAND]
BO_ 2181010688 CHARGER_CONFIGURATION_COMMAND_2: 8 Vector__XXX
    SG_ Instance:        0|8@1+  (1,0)   [0|255]     ""  Vector__XXX
    SG_ Maximum_Charge_Current_As_Percent:        8|8@1+  (0.5,0)   [0|255]     "%"  Vector__XXX
    SG_ Charge_Rate_Limit_As_Percent_Of_Bank_Size:        16|8@1+  (0.5,0)   [0|255]     "%"  Vector__XXX
    SG_ Shore_Breaker_Size:        24|8@1+  (1,0)   [0|255]     "A"  Vector__XXX
    SG_ Default_Battery_Temperature:        32|8@1+  (1,-40)   [-40|215]     "deg C"  Vector__XXX
    SG_ Recharge_Voltage:        40|16@1+  (0.05,0)   [0|65535]    "V"  Vector__XXX

    65535 "Data Invalid";

CM_ "1FF96";
BO_ 2583664194 CHARGER_CONFIGURATION_STATUS_2: 8 Vector__XXX
    SG_ Instance:        0|8@1+  (1,0)   [0|255]     ""  Vector__XXX
    SG_ Maximum_Charge_Current_As_Percent:        8|8@1+  (0.5,0)   [0|255]     "%"  Vector__XXX
    SG_ Charge_Rate_Limit_As_Percent_Of_Bank_Size:        16|8@1+  (0.5,0)   [0|255]     "%"  Vector__XXX
    SG_ Shore_Breaker_Size:        24|8@1+  (1,0)   [0|255]     "A"  Vector__XXX
    SG_ Default_Battery_Temperature:        32|8@1+  (1,-40)   [-40|215]     "deg C"  Vector__XXX
    SG_ Recharge_Voltage:        40|16@1+  (0.05,0)   [0|65535]    "V"  Vector__XXX

    65535 "Data Invalid";

CM_ "1FFD3";
BO_ 2181026560 INVERTER_COMMAND: 8 Vector__XXX
    SG_ Instance:        0|8@1+  (1,0)   [0|255]     ""  Vector__XXX
    SG_ Inverter_Enable:        8|2@1+  (1,0)   [0|3]     ""  Vector__XXX
    SG_ Load_Sense_Enable:        10|2@1+  (1,0)   [0|3]     ""  Vector__XXX
    SG_ Pass_Through_Enable:        12|2@1+  (1,0)   [0|3]     ""  Vector__XXX
    SG_ Skip:        14|2@1+  (1,0)   [0|3]     ""  Vector__XXX
    SG_ Reserved:        16|40@1+  (1,0)   [0|1099511627775]     ""  Vector__XXX
    SG_ Inverter_Enable_On_Startup:        56|2@1+  (1,0)   [0|3]     ""  Vector__XXX
    SG_ Load_Sense_Enable_On_Startup:        58|2@1+  (1,0)   [0|3]     ""  Vector__XXX
    SG_ AC_Pass_Through_Enable_On_Startup:        60|2@1+ (1,0)   [0|3]     ""  Vector__XXX

    0 "Disable"
    1 "Enable inverter"
    3 "No Data";

    0 "Disable load sense"
    1 "Enable load sense"
    3 "No Data";

    0 "Disable pass-through"
    1 "Enable pass-through"
    3 "No Data";

    3 "No Data";

    1099511627775 "No Data";

    0 "Inverter is disabled on startup"
    1 "Inverter is enabled on startup"
    3 "No Data";

    0 "Load sense is disabled on startup"
    1 "Load sense is enabled on startup"
    3 "No Data";

    0 "Pass-through is disabled on startup"
    1 "Pass-through is enabled on startup"
    3 "No Data";

CM_ "Elwell";
CM_ "1FFF7";
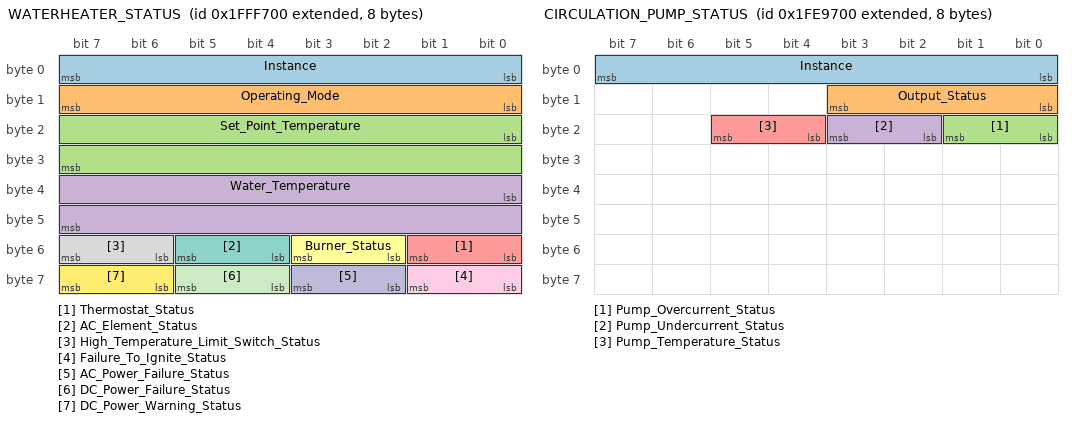
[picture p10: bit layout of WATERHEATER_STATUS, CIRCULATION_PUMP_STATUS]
BO_ 2181035776 WATERHEATER_STATUS: 8  Vector__XXX
    SG_ Instance:        0|8@1+  (1,0)   [0|255] ""    Vector__XXX
    SG_ Operating_Mode:        8|8@1+  (1,0)   [0|255] ""    Vector__XXX
    SG_ Set_Point_Temperature:        16|16@1+  (0.03125,-273) [-8736|56799] "deg C"    Vector__XXX
    SG_ Water_Temperature:        32|16@1+  (0.03125,-273) [-8736|56799] "deg C"    Vector__XXX
    SG_ Thermostat_Status:        48|2@1+  (1,0) [0|3] ""    Vector__XXX
    SG_ Burner_Status:        50|2@1+  (1,0) [0|3] ""    Vector__XXX
    SG_ AC_Element_Status:        52|2@1+  (1,0) [0|3] ""    Vector__XXX
    SG_ High_Temperature_Limit_Switch_Status:        54|2@1+  (1,0) [0|3] ""    Vector__XXX
    SG_ Failure_To_Ignite_Status:        56|2@1+  (1,0) [0|3] ""    Vector__XXX
    SG_ AC_Power_Failure_Status:        58|2@1+  (1,0) [0|3] ""    Vector__XXX
    SG_ DC_Power_Failure_Status:        60|2@1+  (1,0) [0|3] ""    Vector__XXX
    SG_ DC_Power_Warning_Status:        62|2@1+  (1,0) [0|3] ""    Vector__XXX

    0 "Off"
    1 "combustion"
    2 "electric"
    3 "gas/electric (both)"
    255 "Data Invalid";

    65535 "Data Invalid";

    65535 "Data Invalid";

    0 "set point met"
    1 "set point not met (heat is being applied)"
    3 "Data Invalid";

    0 "off"
    1 "burner is lit"
    3 "Data Invalid";

    0 "AC element is inactive"
    1 "AC element is active"
    3 "Data Invalid";

    0 "limit switch not tripped"
    1 "limit switch tripped"
    3 "Data Invalid";

    0 "no failure"
    1 "device has failed to ignite"
    3 "Data Invalid";

    0 "AC power present"
    1 "AC power not present"
    3 "Data Invalid";

    0 "DC power present"
    1 "DC power not present"
    3 "Data Invalid";

    0 "DC power sufficient"
    1 "DC power warning"
    3 "Data Invalid";

CM_ "1FE99";
BO_ 2180946176 WATERHEATER_STATUS_2: 8  Vector__XXX
    SG_ Instance:        0|8@1+  (1,0)   [0|255] ""    Vector__XXX
    SG_ Heat_Level:        8|4@1+  (1,0)   [0|15] ""    Vector__XXX

    0 "Default"
    1 "Low level (ECO)"
    2 "High level (COMFORT)"
    3 "Anti-freezing"
    13 "DeCalc.(status only)"
    15 "Data Invalid";

CM_ "1FFF6";
BO_ 2181035520 WATERHEATER_COMMAND: 8  Vector__XXX
    SG_ Instance:        0|8@1+  (1,0)   [0|255] ""    Vector__XXX
    SG_ Operating_Mode:        8|8@1+  (1,0)   [0|255] ""    Vector__XXX
    SG_ Set_Point_Temperature:        16|16@1+  (0.03125,-273) [-8736|56799] "deg C"    Vector__XXX
    SG_ Electric_Element_Level:        48|4@1+  (1,0) [0|15] ""    Vector__XXX

    0 "off"
    1 "combustion"
    2 "electric"
    3 "gas/electric (both)"
    255 "No Data";

    65535 "No Data";

    15 "No Data";

CM_ "1FE98";
BO_ 2583599104 WATERHEATER_COMMAND_2: 8  Vector__XXX
    SG_ Instance:        0|8@1+  (1,0)   [0|255] ""    Vector__XXX
    SG_ Engine_Preheat:        8|4@1+  (1,0)   [0|16] ""    Vector__XXX
    SG_ Command:        16|8@1+  (1,0) [0|255] ""    Vector__XXX

    0 "off"
    1 "on"
    5 "Test (Forced On)"
    15 "No Data";

    0 "Electric Low - Enable"
    1 "Electric Low - Disable"
    2 "Electric Low - Toggle"
    3 "Electric High - Enable"
    4 "Electric High - Disable"
    5 "Electric High - Toggle"
    6 "Burner - Enable"
    7 "Burner - Disable"
    8 "Burner - Toggle"
    9 "Electric - Cycle (low to high to off)"
    10 "Electric - Cycle (high to low to off)"
    11 "Electric Low Test - Toggle"
    12 "Electric High Test - Toggle"
    13 "Burner Test - Toggle"

    15 "No Data";

CM_ "1FE97";
BO_ 2180945664 CIRCULATION_PUMP_STATUS: 8  Vector__XXX
    SG_ Instance:        0|8@1+  (1,0)   [0|255] ""    Vector__XXX
    SG_ Output_Status:        8|4@1+  (1,0)   [0|255] ""    Vector__XXX
    SG_ Pump_Overcurrent_Status:        16|2@1+  (1,0)   [0|3] ""    Vector__XXX
    SG_ Pump_Undercurrent_Status:        18|2@1+  (1,0)   [0|3] ""    Vector__XXX
    SG_ Pump_Temperature_Status:        20|2@1+  (1,0)   [0|3] ""    Vector__XXX

    0 "off"
    1 "on"
    5 "Test (Forced On)"
    15 "Data Invalid";

    0 "No overcurrent detected"
    1 "Overcurrent detected"
    3 "Data Invalid";

    0 "No Undercurrent detected"
    1 "Undercurrent detected"
    3 "Data Invalid";

    0 "Temperature normal"
    1 "Temperature warning"
    3 "Data Invalid";

CM_ "1FE96";
BO_ 2180945408 CIRCULATION_PUMP_COMMAND: 8  Vector__XXX
    SG_ Instance:        0|8@1+  (1,0)   [0|255] ""    Vector__XXX
    SG_ Output_Mode:        8|4@1+  (1,0)   [0|255] ""    Vector__XXX

    0 "off"
    5 "Test (Forced On)"
    15 "No Data";

CM_ "1FFE4";
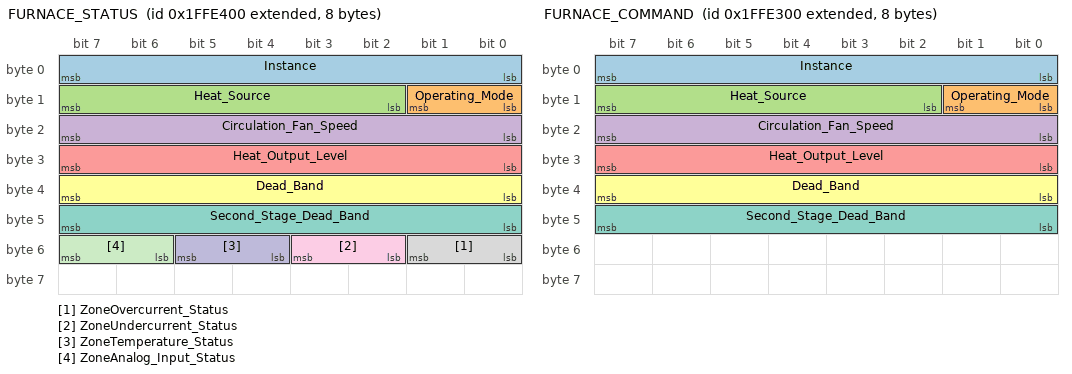
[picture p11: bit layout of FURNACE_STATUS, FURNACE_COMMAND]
BO_ 2181030912 FURNACE_STATUS: 8  Vector__XXX
    SG_ Instance:        0|8@1+  (1,0)   [0|255] ""    Vector__XXX
    SG_ Operating_Mode:        8|2@1+  (1,0)   [0|3] ""    Vector__XXX
    SG_ Heat_Source:        10|6@1+  (1,0)   [0|63] ""    Vector__XXX
    SG_ Circulation_Fan_Speed:        16|8@1+  (0.5,0)   [0|255] "%"    Vector__XXX
    SG_ Heat_Output_Level:        24|8@1+  (0.5,0)   [0|255] "%"    Vector__XXX
    SG_ Dead_Band:        32|8@1+  (1,-40)   [-40|215] "deg C"    Vector__XXX
    SG_ Second_Stage_Dead_Band:        40|8@1+  (1,-40)   [-40|215] "deg C"    Vector__XXX
    SG_ ZoneOvercurrent_Status:        48|2@1+  (1,0)   [0|3] ""    Vector__XXX
    SG_ ZoneUndercurrent_Status:        50|2@1+  (1,0)   [0|3] ""    Vector__XXX
    SG_ ZoneTemperature_Status:        52|2@1+  (1,0)   [0|3] ""    Vector__XXX
    SG_ ZoneAnalog_Input_Status:        54|2@1+  (1,0)   [0|3] ""    Vector__XXX

    1 "Zone 1"
    2 "Zone 2"
    3 "Zone 3"
    4 "Zone 4"
    5 "Zone 5";

    0 "Automatic"
    1 "Manual"
    3 "Data invalid";

    0 "Combustion"
    1 "AC power primary"
    2 "AC power secondary"
    3 "Engine heat"
    63 "Data invalid";

    0 "No overcurrent detected"
    1 "Overcurrent detected"
    3 "Data invalid";

    0 "No undercurrent detected"
    1 "Undercurrent detected"
    3 "Data invalid";

    0 "Temperature normal"
    1 "Temperature warning"
    3 "Data invalid";

    0 "Off (Inactive)"
    1 "On (Active)"
    3 "Data invalid";

CM_ "1FFE3";
BO_ 2181030656 FURNACE_COMMAND: 8  Vector__XXX
    SG_ Instance:        0|8@1+  (1,0)   [0|255] ""    Vector__XXX
    SG_ Operating_Mode:        8|2@1+  (1,0)   [0|3] ""    Vector__XXX
    SG_ Heat_Source:        10|6@1+  (1,0)   [0|63] ""    Vector__XXX
    SG_ Circulation_Fan_Speed:        16|8@1+  (0.5,0)   [0|255] "%"    Vector__XXX
    SG_ Heat_Output_Level:        24|8@1+  (0.5,0)   [0|255] "%"    Vector__XXX
    SG_ Dead_Band:        32|8@1+  (1,-40)   [-40|215] "deg C"    Vector__XXX
    SG_ Second_Stage_Dead_Band:        40|8@1+  (1,-40)   [-40|215] "deg C"    Vector__XXX

    1 "Zone 1"
    2 "Zone 2"
    3 "Zone 3"
    4 "Zone 4"
    5 "Zone 5";

    0 "Automatic"
    1 "Manual"
    3 "Data invalid";

    0 "Combustion"
    1 "AC power primary"
    2 "AC power secondary"
    3 "Engine heat"
    63 "Data invalid";

CM_ "1FFAD";
BO_ 2181016832 ATS_AC_STATUS_1: 8  Vector__XXX
    SG_ Transfer_Switch_Instance:        0|3@1+  (1,0)   [0|7] ""    Vector__XXX
    SG_ Input_Output_Type:        3|1@1+  (1,0)   [0|1] ""    Vector__XXX
    SG_ Source:        4|3@1+  (1,0)   [0|7] ""    Vector__XXX
    SG_ Leg:        7|1@1+  (1,0)   [0|1] ""    Vector__XXX

    0 "Invalid Instance"
    7 "Invalid Instance";

    0 "Input"
    1 "Output";

    0 "Primary"
    1 "Secondary"
    7 "Data Invalid";

    0 "Leg1"
    1 "Leg2";

CM_ "1FFAB";
BO_ 2181016320 ATS_AC_STATUS_3: 8  Vector__XXX
    SG_ Transfer_Switch_Instance:        0|3@1+  (1,0)   [0|7] ""    Vector__XXX
    SG_ Input_Output_Type:        3|1@1+  (1,0)   [0|1] ""    Vector__XXX
    SG_ Source:        4|3@1+  (1,0)   [0|7] ""    Vector__XXX
    SG_ Leg:        7|1@1+  (1,0)   [0|1] ""    Vector__XXX

    0 "Invalid Instance"
    7 "Invalid Instance";

    0 "Input"
    1 "Output";

    0 "Primary"
    1 "Secondary"
    7 "Data Invalid";

    0 "Leg1"
    1 "Leg2";

CM_ "1FE87";
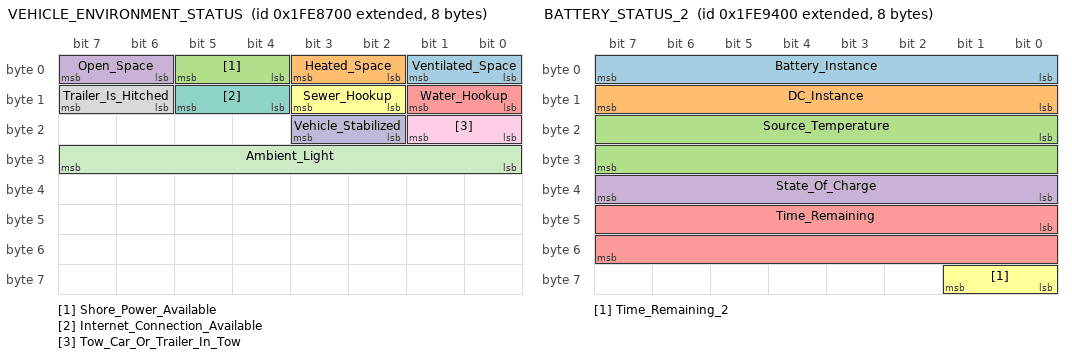
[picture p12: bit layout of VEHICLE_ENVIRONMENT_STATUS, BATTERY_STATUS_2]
BO_ 2180941568 VEHICLE_ENVIRONMENT_STATUS: 8  Vector__XXX
    SG_ Ventilated_Space:        0|2@1+  (1,0)   [0|3] ""    Vector__XXX
    SG_ Heated_Space:        2|2@1+  (1,0)   [0|3] ""    Vector__XXX
    SG_ Shore_Power_Available:        4|2@1+  (1,0)   [0|3] ""    Vector__XXX
    SG_ Open_Space:        6|2@1+  (1,0)   [0|3] ""    Vector__XXX
    SG_ Water_Hookup:        8|2@1+  (1,0)   [0|3] ""    Vector__XXX
    SG_ Sewer_Hookup:        10|2@1+  (1,0)   [0|3] ""    Vector__XXX
    SG_ Internet_Connection_Available:        12|2@1+  (1,0)   [0|3] ""    Vector__XXX
    SG_ Trailer_Is_Hitched:        14|2@1+  (1,0)   [0|3] ""    Vector__XXX
    SG_ Tow_Car_Or_Trailer_In_Tow:        16|2@1+  (1,0)   [0|3] ""    Vector__XXX
    SG_ Vehicle_Stabilized:        18|2@1+  (1,0)   [0|3] ""    Vector__XXX
    SG_ Ambient_Light:        24|8@1+  (0.5,0)   [0|255] "%"    Vector__XXX

    0 "RV is in a ventilated space"
    1 "Space is not ventilated"
    2 "Cannot be Determined"
    3 "Data Invalid";

    0 "RV is in a heated space"
    1 "Space is not heated"
    2 "Cannot be Determined"
    3 "Data Invalid";

    0 "No Shore Power"
    1 "AC power from the shore cord is available."
    2 "Cannot be Determined"
    3 "Data Invalid";

    0 "RV is in an open space"
    1 "RV is in a confined space"
    2 "Cannot be Determined"
    3 "Data Invalid";

    0 "No hookup"
    1 "The vehicle is connected to a fresh water supply"
    2 "Cannot be Determined"
    3 "Data Invalid";

    0 "No hookup"
    1 "The vehicle is connected to a sewer system"
    2 "Cannot be Determined"
    3 "Data Invalid";

    0 "No internet connection is available"
    1 "An internet connection is available"
    2 "Cannot be Determined"
    3 "Data Invalid";

    0 "This trailer is not hitched to a tow vehicle"
    1 "This trailer is hitched to a tow vehicle"
    2 "Cannot be Determined"
    3 "Data Invalid";

    0 "No trailer or tow car is present"
    1 "A trailer or tow car is presently hitched behind"
    2 "Cannot be Determined"
    3 "Data Invalid";

    0 "Not stabilized"
    1 "Jacks or other stabilization method is fully deployed"
    2 "Cannot be Determined"
    3 "Data Invalid";

    255 "Data Invalid";

CM_ "1FE94";
BO_ 2180944896 BATTERY_STATUS_2: 8  Vector__XXX
    SG_ Battery_Instance:        0|8@1+  (1,0)   [0|255] ""    Vector__XXX
    SG_ DC_Instance:        8|8@1+  (1,0)   [0|255] ""    Vector__XXX
    SG_ Source_Temperature:        16|16@1+  (0.03125,-273) [-8736|56799] "deg C"    Vector__XXX
    SG_ State_Of_Charge:        32|8@1+  (0.5,0)   [0|255] "%"    Vector__XXX
    SG_ Time_Remaining:        40|16@1+  (1,0)   [0|65535] "min"    Vector__XXX
    SG_ Time_Remaining_2:        56|2@1+  (1,0)   [0|3] ""    Vector__XXX

    0 "Time to Empty";

CM_ "1FEF1";
BO_ 2180968704 TIRE_RAW_STATUS: 8  Vector__XXX
    SG_ Sensor_ID:        0|32@1+  (1,0)   [0|4294967295] ""    Vector__XXX
    SG_ Tire_Pressure:        32|16@1+  (1,0)   [0|65635] "kPa"    Vector__XXX
    SG_ Tire_Temperature:        48|16@1+  (0.03125,-273) [-8736|56799] "deg C"    Vector__XXX

CM_ "1FFF4";
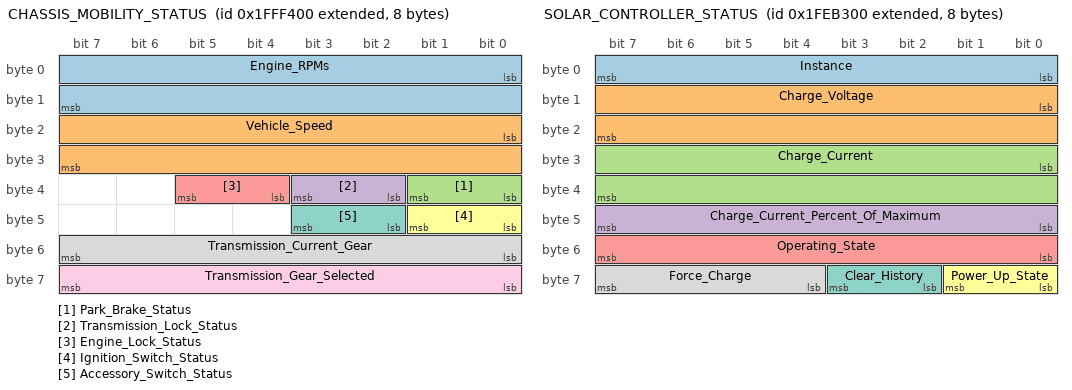
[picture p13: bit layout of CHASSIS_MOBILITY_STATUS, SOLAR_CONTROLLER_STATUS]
BO_ 2181035008 CHASSIS_MOBILITY_STATUS: 8  Vector__XXX
    SG_ Engine_RPMs:        0|16@1+  (0.125,0)   [0|525080] "rpm"    Vector__XXX
    SG_ Vehicle_Speed:        16|16@1+  (0.00390625,0)   [0|16776960] "kph"    Vector__XXX
    SG_ Park_Brake_Status:        32|2@1+  (1,0)   [0|3] ""    Vector__XXX
    SG_ Transmission_Lock_Status:        34|2@1+  (1,0)   [0|3] ""    Vector__XXX
    SG_ Engine_Lock_Status:        36|2@1+  (1,0)   [0|3] ""    Vector__XXX
    SG_ Ignition_Switch_Status:        40|2@1+  (1,0)   [0|3] ""    Vector__XXX
    SG_ Accessory_Switch_Status:        42|2@1+  (1,0)   [0|3] ""    Vector__XXX
    SG_ Transmission_Current_Gear:        48|8@1+  (1,0)   [0|255] ""    Vector__XXX
    SG_ Transmission_Gear_Selected:        56|8@1+  (1,0)   [0|255] ""    Vector__XXX

    65534 "Error"
    65535 "Data Invalid";

    65534 "Error"
    65535 "Data Invalid";

    0 "Park Brake Released. Coach is free to roll"
    1 "Park Brake Engaged. Coach is immobilized"
    3 "Data Invalid";

    0 "Transmission_Lock_Status"
    1 "Transmission is locked (shall not go into gear)"
    3 "Data Invalid";

    0 "Engine is free to start"
    1 "Engine is locked"
    3 "Data Invalid";

    0 "Off"
    1 "On"
    3 "Data Invalid";

    0 "Off"
    1 "On"
    3 "Data Invalid";

    124 "Reverse 1"
    125 "Neutral"
    126 "Forward 1"
    127 "Forward 2"
    251 "Park"
    255 "Data Invalid";

    124 "Reverse 1"
    125 "Neutral"
    126 "Forward 1"
    127 "Forward 2"
    251 "Park"
    255 "Data Invalid";

CM_ "1FEF4";
BO_ 2180969472 THERMOSTAT_SCHEDULE_COMMAND_2: 8  Vector__XXX
    SG_ Instance:        0|8@1+  (1,0)   [0|255] ""    Vector__XXX
    SG_ Schedule_Mode_Instance:        8|8@1+  (1,0)   [0|255] ""    Vector__XXX
    SG_ Start_Hour:        16|8@1+  (1,0)   [0|255] "h"    Vector__XXX
    SG_ Start_Minute:        24|8@1+  (1,0)   [0|255] "min"    Vector__XXX
    SG_ Setpoint_Temp_Heat:        32|16@1+  (0.03125,-273) [-8736|56799] "deg C"    Vector__XXX
    SG_ Setpoint_Temp_Cool:        48|16@1+  (0.03125,-273) [-8736|56799] "deg C"    Vector__XXX

    0 "Sleep"
    1 "Wake"
    2 "Away"
    3 "Return"
    250 "Storage"
    255 "Data Invalid";

    0 "12:00 AM"
    12 "12:00 Noon"
    23 "11:00 PM"
    255 "Data Invalid";

CM_ "1FEB3";
BO_ 2180952832 SOLAR_CONTROLLER_STATUS: 8  Vector__XXX
    SG_ Instance:        0|8@1+  (1,0)   [0|255] ""    Vector__XXX
    SG_ Charge_Voltage:        8|16@1+  (0.05,0)   [0|65535]     "V"  Vector__XXX
    SG_ Charge_Current:        24|16@1+    (0.05,-1600)   [-32000|33535]   "A"     Vector__XXX
    SG_ Charge_Current_Percent_Of_Maximum:        40|8@1+    (0.5,0)   [0|255]   "%"     Vector__XXX
    SG_ Operating_State:        48|8@1+    (1,0)   [0|255]   ""     Vector__XXX
    SG_ Power_Up_State:        56|2@1+    (1,0)   [0|3]   ""     Vector__XXX
    SG_ Clear_History:        58|2@1+    (1,0)   [0|3]   ""     Vector__XXX
    SG_ Force_Charge:        60|4@1+    (1,0)   [0|15]   ""     Vector__XXX

    0 "Undefined"
    1 "Do not charge"
    2 "Bulk"
    3 "Absorption"
    4 "Overcharge"
    5 "Equalize"
    6 "Float"
    7 "Constant voltage / Current"
    255 "Data Invalid";

    0 "controller disabled"
    1 "controller enabled"
    3 "Data Invalid";

    0 "History not clear"
    1 "History cleared"
    3 "Data Invalid";

    0 "Charging is NOT forced"
    1 "Force charge to bulk"
    2 "Force charge to float"
    3 "Data Invalid";

    65535 "Data Invalid";

    65535 "Data Invalid";

CM_ "1FE80";
BO_ 2180939776 SOLAR_CONTROLLER_BATTERY_STATUS: 8  Vector__XXX
    SG_ Instance:        0|8@1+  (1,0)   [0|255] ""    Vector__XXX
    SG_ DC_Source_Instance:        8|8@1+  (1,0)   [0|255] ""    Vector__XXX
    SG_ Charger_Priority:        16|8@1+  (1,0)   [0|255] ""    Vector__XXX
    SG_ Measured_Voltage:        24|16@1+  (0.05,0)   [0|65535]     "V"  Vector__XXX
    SG_ Measured_Current:        40|16@1+    (0.05,-1600)   [-32000|33535]   "A"     Vector__XXX
    SG_ Measured_Temperature:        56|8@1+  (1,-40) [-40|215] "deg C"    Vector__XXX

CM_ "1FDFF";
BO_ 2180906752 SOLAR_CONTROLLER_SOLAR_ARRAY_STATUS: 8  Vector__XXX
    SG_ Instance:        0|8@1+  (1,0)   [0|255] ""    Vector__XXX
    SG_ Solar_Array_Measured_Voltage:        8|16@1+  (0.05,0)   [0|65535]     "V"  Vector__XXX
    SG_ Solar_Array_Measured_Input_Current:        24|16@1+    (0.05,-1600)   [-32000|33535]   "A"     Vector__XXX

CM_ "1FE85";
BO_ 2180941056 SOLAR_CONTROLLER_STATUS_2: 8  Vector__XXX
    SG_ Instance:        0|8@1+  (1,0)   [0|255] ""    Vector__XXX
    SG_ Rated_Battery_Voltage:        8|16@1+  (0.05,0)   [0|65535]     "V"  Vector__XXX
    SG_ Rated_Charging_Current:        24|16@1+    (0.05,-1600)   [-32000|33535]   "A"     Vector__XXX

    65535 "Invalid Data";

    65535 "Invalid Data";

CM_ "1FE83";
BO_ 2180940544 SOLAR_CONTROLLER_STATUS_4: 8  Vector__XXX
    SG_ Instance:        0|8@1+  (1,0)   [0|255] ""    Vector__XXX
    SG_ Todays_Amp_Hours_To_Battery:        8|16@1+  (1,0)   [0|65535] "Ah"    Vector__XXX
    SG_ Yesterdays_Amp_Hours_To_Battery:        24|16@1+  (1,0)   [0|65535] "Ah"    Vector__XXX
    SG_ Day_Before_Yesterdays_Amp_Hours_To_Battery:        40|16@1+  (1,0)   [0|65535] "Ah"    Vector__XXX

CM_ "1FE9F";
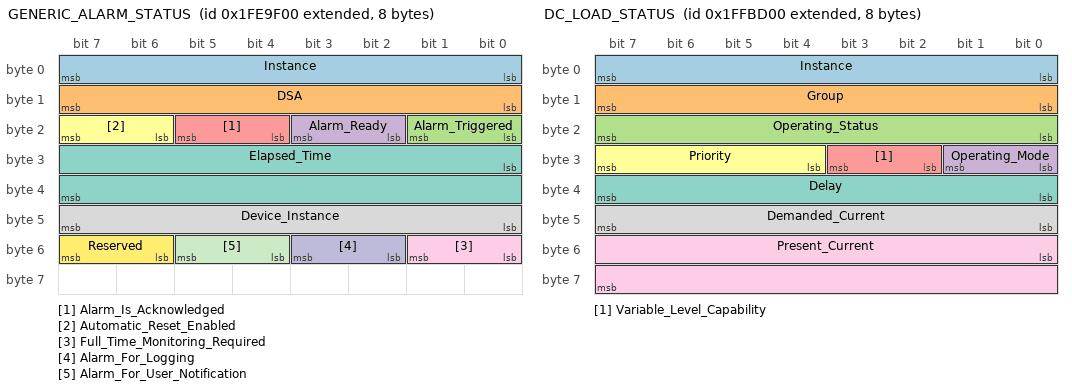
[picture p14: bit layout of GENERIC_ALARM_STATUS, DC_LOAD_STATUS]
BO_ 2180947712 GENERIC_ALARM_STATUS: 8  Vector__XXX
    SG_ Instance:        0|8@1+  (1,0)   [0|255] ""    Vector__XXX
    SG_ DSA:        8|8@1+  (1,0)   [0|255] ""    Vector__XXX
    SG_ Alarm_Triggered:        16|2@1+  (1,0)   [0|3] ""    Vector__XXX
    SG_ Alarm_Ready:        18|2@1+  (1,0)   [0|3] ""    Vector__XXX
    SG_ Alarm_Is_Acknowledged:        20|2@1+  (1,0)   [0|3] ""    Vector__XXX
    SG_ Automatic_Reset_Enabled:        22|2@1+  (1,0)   [0|3] ""    Vector__XXX
    SG_ Elapsed_Time:        24|16@1+  (1,0)   [0|65535] "min"    Vector__XXX
    SG_ Device_Instance:        40|8@1+  (1,0)   [0|255] ""    Vector__XXX
    SG_ Full_Time_Monitoring_Required:        48|2@1+  (1,0)   [0|3] ""    Vector__XXX
    SG_ Alarm_For_Logging:        50|2@1+  (1,0)   [0|3] ""    Vector__XXX
    SG_ Alarm_For_User_Notification:        52|2@1+  (1,0)   [0|3] ""    Vector__XXX
    SG_ Reserved:        54|2@1+  (1,0)   [0|3] ""    Vector__XXX

    0 "Generic"
    63 "Generic"
    64 "DSA of the device function"
    253 "DSA of the device function"
    255 "Data Invalid";

    0 "Alarm is not Triggered"
    1 "Alarm is Triggered"
    3 "Data Invalid";

    0 "Alarm condition is not being monitored"
    1 "Alarm condition is being monitored"
    3 "Data Invalid";

    0 "Alarm has not been acknowledged"
    1 "Alarm has been triggered and acknowledged"
    3 "Data Invalid";

    0 "Alarm will not automatically return to the Ready State"
    1 "Alarm will automatically return to the Ready State once an “Ok” condition is"
    3 "Data Invalid";

    255 "All Instances";

    0 "Full-Time monitoring of alarm is not required"
    1 "Full-Time monitoring of alarm is required"
    3 "Data Invalid";

    0 "Do not log alarm now"
    1 "Alarm should be logged for statistical or forensic purposes"
    3 "Data Invalid";

    0 "Do not notify user"
    1 "User notification required"
    3 "Data Invalid";

CM_ "1FFBD";
BO_ 2181020928 DC_LOAD_STATUS: 8  Vector__XXX
    SG_ Instance:        0|8@1+  (1,0)   [0|255] ""    Vector__XXX
    SG_ Group:        8|8@1+  (1,0)   [0|255] ""    Vector__XXX
    SG_ Operating_Status:        16|8@1+  (0.5,0)   [0|255] "%"    Vector__XXX
    SG_ Operating_Mode:        24|2@1+  (1,0)   [0|3] ""    Vector__XXX
    SG_ Variable_Level_Capability:        26|2@1+  (1,0)   [0|3] ""    Vector__XXX
    SG_ Priority:        28|4@1+  (1,0)   [0|15] ""    Vector__XXX
    SG_ Delay:        32|8@1+  (1,0)   [0|255] "sec"    Vector__XXX
    SG_ Demanded_Current:        40|8@1+    (1,0)   [0|255]   "A"     Vector__XXX
    SG_ Present_Current:        48|16@1+    (0.05,-1600)   [-32000|33535]   "A"     Vector__XXX

    0 "All groups"
    255 "Data Invalid";

    252 "Load delay active"
    255 "Data Invalid";

    0 "Automatic"
    1 "Manual"
    3 "Data Invalid";

    0 "Not variable (not dimmable)"
    1 "Variable (dimmable)"
    3 "Data Invalid";

    0 "Highest priority"
    13 "Lowest priority"
    14 "Error"
    15 "Data Invalid";

    0 "sec"
    240 "sec"
    241 "5 minutes"
    250 "14 minutes"
    255 "Data Invalid";

CM_ "1FFE0";
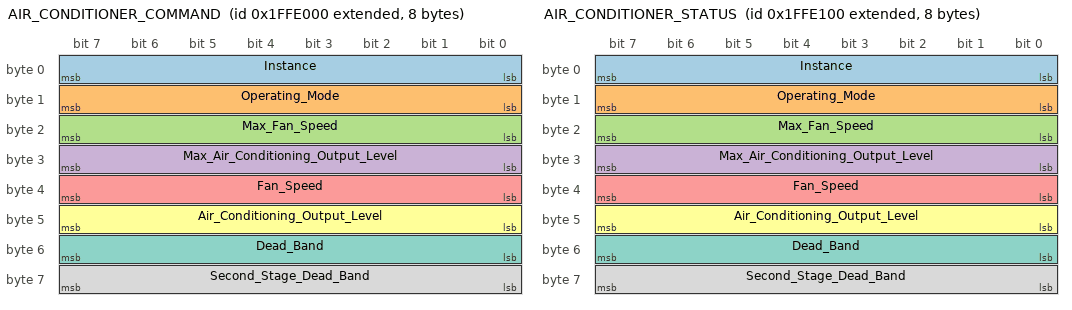
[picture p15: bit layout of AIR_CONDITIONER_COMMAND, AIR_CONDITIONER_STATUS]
BO_ 2181029888 AIR_CONDITIONER_COMMAND: 8  Vector__XXX
    SG_ Instance:        0|8@1+  (1,0)   [0|255] ""    Vector__XXX
    SG_ Operating_Mode:        8|8@1+  (1,0)   [0|255] ""    Vector__XXX
    SG_ Max_Fan_Speed:        16|8@1+  (0.5,0)   [0|255] "%"    Vector__XXX
    SG_ Max_Air_Conditioning_Output_Level:        24|8@1+  (0.5,0)   [0|255] "%"    Vector__XXX
    SG_ Fan_Speed:        32|8@1+  (0.5,0)   [0|255] "%"    Vector__XXX
    SG_ Air_Conditioning_Output_Level:        40|8@1+  (0.5,0)   [0|255] "%"    Vector__XXX
    SG_ Dead_Band:        48|8@1+  (1,-40) [-40|215] "deg C"    Vector__XXX
    SG_ Second_Stage_Dead_Band :        56|8@1+  (1,-40) [-40|215] "deg C"    Vector__XXX

    0 "Automatic"
    1 "Manual"
    255 "Data Invalid";

CM_ "1FFE1";
BO_ 2181030144 AIR_CONDITIONER_STATUS: 8  Vector__XXX
    SG_ Instance:        0|8@1+  (1,0)   [0|255] ""    Vector__XXX
    SG_ Operating_Mode:        8|8@1+  (1,0)   [0|255] ""    Vector__XXX
    SG_ Max_Fan_Speed:        16|8@1+  (0.5,0)   [0|255] "%"    Vector__XXX
    SG_ Max_Air_Conditioning_Output_Level:        24|8@1+  (0.5,0)   [0|255] "%"    Vector__XXX
    SG_ Fan_Speed:        32|8@1+  (0.5,0)   [0|255] "%"    Vector__XXX
    SG_ Air_Conditioning_Output_Level:        40|8@1+  (0.5,0)   [0|255] "%"    Vector__XXX
    SG_ Dead_Band:        48|8@1+  (1,-40) [-40|215] "deg C"    Vector__XXX
    SG_ Second_Stage_Dead_Band :        56|8@1+  (1,-40) [-40|215] "deg C"    Vector__XXX

    0 "Automatic"
    1 "Manual"
    255 "Data Invalid";

CM_ "1FE95";
BO_ 2180945152 BATTERY_STATUS_1: 8  Vector__XXX
    SG_ Battery_Instance:        0|8@1+  (1,0)   [0|255] ""    Vector__XXX
    SG_ DC_Instance:        8|8@1+  (1,0)   [0|255] ""    Vector__XXX
    SG_ DC_Voltage:        16|16@1+  (0.05,0)   [0|65535]     "V"  Vector__XXX
    SG_ DC_Current:        32|32@1+    (0.001,-2000000)   [-2000000000|2294967295]   "A"     Vector__XXX

     CM_ "1FFBF";
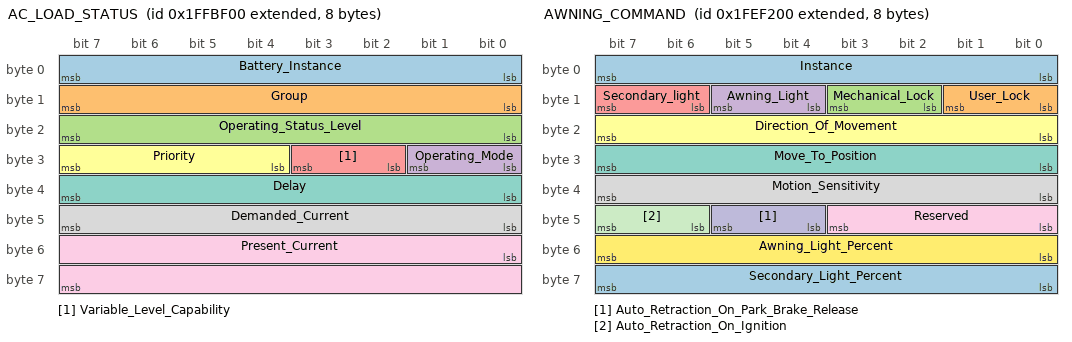
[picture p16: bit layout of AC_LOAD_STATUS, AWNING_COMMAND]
BO_ 2181021440 AC_LOAD_STATUS: 8  Vector__XXX
    SG_ Battery_Instance:        0|8@1+  (1,0)   [0|255] ""    Vector__XXX
    SG_ Group:        8|8@1+  (1,0)   [0|255] ""    Vector__XXX
    SG_ Operating_Status_Level:        16|8@1+  (0.5,0)   [0|255] "%"    Vector__XXX
    SG_ Operating_Mode:        24|2@1+  (1,0)   [0|3] ""    Vector__XXX
    SG_ Variable_Level_Capability:        26|2@1+  (1,0)   [0|3] ""    Vector__XXX
    SG_ Priority:        28|4@1+  (1,0)   [0|15] ""    Vector__XXX
    SG_ Delay:        32|8@1+  (1,0)   [0|255] "s"    Vector__XXX
    SG_ Demanded_Current:        40|8@1+    (1,0)   [0|255]   "A"     Vector__XXX
    SG_ Present_Current:        48|16@1+    (0.05,-1600)   [-32000|33535]   "A"     Vector__XXX

    0 "All groups"
    255 "No data";

    252 "Load delay active"
    255 "Data Invalid";

    0 "Automatic"
    1 "Manual"
    3 "Data Invalid";

    0 "Not variable"
    1 "Variable"
    3 "Data Invalid";

    0 "Highest priority"
    13 "Lowest priority"
    14 "Error"
    15 "No data";

    241 "5 minutes"
    250 "14 minutes"
    255 "Data Invalid";

CM_ "1FEA8";
BO_ 2180950016 CHASSIS_MOBILITY_STATUS_2: 8  Vector__XXX
    SG_ Steering_Wheel_Angle:        0|16@1+  (0.0009765625,-31.374)   [-32126.976|33408.024] "rad"    Vector__XXX
    SG_ Headlight_Switch:        16|2@1+  (1,0)   [0|3] ""    Vector__XXX
    SG_ Fuel_Level_Percent:        24|8@1+  (0.5,0)   [0|255] "%"    Vector__XXX
    SG_ Odometer:        32|32@1+  (5,0)   [0|4294967295] ""    Vector__XXX

    65534 "Error"
    65535 "Data Invalid";

    0 "Headlight Switch Off"
    1 "Headlight Switch On"
    3 "Data Invalid";

CM_ "1FEEE";
BO_ 2180967936 TIRE_TEMPERATURE_CONFIGURATION_STATUS: 8  Vector__XXX
    SG_ Reserved:        0|4@1+  (1,0)   [0|15] ""    Vector__XXX
    SG_ Tire_Location_Axle:        4|4@1+  (1,0)   [0|15] ""    Vector__XXX
    SG_ Extremely_High_Tire_Temperature:        8|16@1+  (0.03125,-273) [-8736|56799] "deg C"    Vector__XXX
    SG_ High_Tire_Temperature:        24|16@1+  (0.03125,-273) [-8736|56799] "deg C"    Vector__XXX
    SG_ Low_Battery_Level:        40|8@1+  (0.02,0) [0|255] "V"    Vector__XXX

    15 "Data Invalid";

    0 "Steer axle"
    1 "Drive Axle"
    2 "Tag axle"
    3 "Trailer/ Tow/ Spare Tire axle"
    15 "Data Invalid";

CM_ "1FEF5";
BO_ 2180969728 THERMOSTAT_SCHEDULE_COMMAND_1: 8  Vector__XXX
    SG_ Instance:        0|8@1+  (1,0)   [0|255] ""    Vector__XXX
    SG_ Schedule_Mode_Instance:        8|8@1+  (1,0)   [0|255] ""    Vector__XXX
    SG_ Start_Hour:        16|8@1+  (1,0)   [0|255] "h"    Vector__XXX
    SG_ Start_Minute:        24|8@1+  (1,0)   [0|255] "min"    Vector__XXX
    SG_ Setpoint_Temp_Heat:        32|16@1+  (0.03125,-273) [-8736|56799] "deg C"    Vector__XXX
    SG_ Setpoint_Temp_Cool:        48|16@1+  (0.03125,-273) [-8736|56799] "deg C"    Vector__XXX

    0 "Sleep"
    1 "Wake"
    2 "Away"
    3 "Return"
    250 "Storage"
    255 "Data Invalid";

    0 "12:00 AM"
    12 "12:00 Noon"
    23 "11:00 PM"
    255 "Data Invalid";

CM_ "1FE82";
BO_ 2180940288 SOLAR_CONTROLLER_STATUS_5: 8  Vector__XXX
    SG_ Instance:        0|8@1+  (1,0)   [0|255] ""    Vector__XXX
    SG_ Last_7_Days_Amp_Hours_To_Battery:        8|16@1+  (1,0)   [0|65535] "Ah"    Vector__XXX
    SG_ Cumulative_Power_Generation:        24|32@1+  (1,0)   [0|4294967295] "kWh"    Vector__XXX

CM_ "1FE81";
BO_ 2180940032 SOLAR_CONTROLLER_STATUS_6: 8  Vector__XXX
    SG_ Instance:        0|8@1+  (1,0)   [0|255] ""    Vector__XXX
    SG_ Total_Number_Of_Operating_Days:        8|16@1+  (1,0)   [0|65535] "days"    Vector__XXX
    SG_ Solar_Charge_Controller_Measured_Temperature:        24|16@1+  (0.03125,-273) [-8736|56799] "deg C"    Vector__XXX

CM_ "1FEF2";
BO_ 2180968960 AWNING_COMMAND: 8  Vector__XXX
    SG_ Instance:        0|8@1+  (1,0)   [0|255] ""    Vector__XXX
    SG_ User_Lock:        8|2@1+  (1,0)   [0|3] ""    Vector__XXX
    SG_ Mechanical_Lock:        10|2@1+  (1,0)   [0|3] ""    Vector__XXX
    SG_ Awning_Light:        12|2@1+  (1,0)   [0|3] ""    Vector__XXX
    SG_ Secondary_light:        14|2@1+  (1,0)   [0|3] ""    Vector__XXX
    SG_ Direction_Of_Movement:        16|8@1+  (1,0)   [0|255] ""    Vector__XXX
    SG_ Move_To_Position:        24|8@1+  (0.5,0)   [0|255] "%"    Vector__XXX
    SG_ Motion_Sensitivity:        32|8@1+  (1,0)   [0|255] ""    Vector__XXX
    SG_ Reserved:        40|4@1+  (1,0)   [0|15] ""    Vector__XXX
    SG_ Auto_Retraction_On_Park_Brake_Release:        44|2@1+  (1,0)   [0|3] ""    Vector__XXX
    SG_ Auto_Retraction_On_Ignition:        46|2@1+  (1,0)   [0|3] ""    Vector__XXX
    SG_ Awning_Light_Percent:        48|8@1+  (0.5,0)   [0|255] "%"    Vector__XXX
    SG_ Secondary_Light_Percent:        56|8@1+  (0.5,0)   [0|255] "%"    Vector__XXX

    0 "All"
    1 "Awning 1 (main patio awning)"
    2 "Awning 2"
    253 "Awning 2";

    0 "Release user lock"
    1 "Set user lock"
    3 "Data Invalid";

    0 "Disengage lock"
    1 "Engage lock"
    3 "Data Invalid";

    0 "Set integrated awning light off, if present"
    1 "Set integrated awning light on"
    3 "Data Invalid";

    0 "Set secondary awning light off, if present"
    1 "Set secondary awning light on"
    3 "Data Invalid";

    0 "Stop"
    1 "Extend"
    2 "Retract"
    255 "Data Invalid";

    0 "Full Retraction"
    200 "Full Extention"
    255 "Data Invalid";

    0 "No motion"
    1 "Extending"
    2 "Retracting"
    255 "Data Invalid";

    15 "Data Invalid";

    0 "No auto retraction based on park brake"
    1 "Set awning to automatically retract with park brake release"
    3 "Data Invalid";

    0 "No auto retraction based on park brake"
    1 "Set awning to automatically retract with ignition."
    3 "Data Invalid";

CM_ "1FEF3";
BO_ 2180969216 AWNING_STATUS: 8  Vector__XXX
    SG_ Instance:        0|8@1+  (1,0)   [0|255] ""    Vector__XXX
    SG_ Motion:        8|8@1+  (1,0)   [0|255] ""    Vector__XXX
    SG_ Position:        16|8@1+  (0.5,0)   [0|255] "%"    Vector__XXX
    SG_ Travel_Lock_Status:        24|2@1+  (1,0)   [0|3] ""    Vector__XXX
    SG_ Unlock_Status:        26|2@1+  (1,0)   [0|3] ""    Vector__XXX
    SG_ User_Lock_Status:        28|2@1+  (1,0)   [0|3] ""    Vector__XXX
    SG_ Brake_Status:        30|2@1+  (1,0)   [0|3] ""    Vector__XXX
    SG_ Parked_Status:        32|2@1+  (1,0)   [0|3] ""    Vector__XXX
    SG_ Ignition_Key:        34|2@1+  (1,0)   [0|3] ""    Vector__XXX
    SG_ Low_Voltage:        36|2@1+  (1,0)   [0|3] ""    Vector__XXX
    SG_ Generic_Lock:        38|2@1+  (1,0)   [0|3] ""    Vector__XXX
    SG_ Awning_Light:        40|2@1+  (1,0)   [0|3] ""    Vector__XXX
    SG_ Secondary_Light:        42|2@1+  (1,0)   [0|3] ""    Vector__XXX
    SG_ Auto_Retraction_On_Park_Brake_Release:        44|2@1+  (1,0)   [0|3] ""    Vector__XXX
    SG_ Auto_Retraction_On_Ignition:        46|2@1+  (1,0)   [0|3] ""    Vector__XXX
    SG_ Awning_Light_Brightness:        48|8@1+  (0.5,0)   [0|255] "%"    Vector__XXX
    SG_ Secondary_Light_Brightness:        56|8@1+  (0.5,0)   [0|255] "%"    Vector__XXX

    0 "No motion"
    1 "Extending"
    2 "Retracting"
    255 "Data Invalid";

    0 "Retracted"
    200 "100% Extended"
    255 "Data Invalid";

    0 "Awning is secured"
    1 "Awning is not secured"
    3 "Data Invalid";

    0 "Awning is unlocked and ready to move"
    1 "Awning is not unlocked and should not be moved"
    3 "Data Invalid";

    0 "User lock is not activated"
    1 "User lock is activated. Awning will not move"
    3 "Data Invalid";

    0 "All motor brakes are not locked"
    1 "One or more motor brakes are locked"
    3 "Data Invalid";

    0 "Awning may move"
    1 "Awning will not move because of Parked status"
    3 "Data Invalid";

    0 "Awning may move"
    1 "Awning will not move because of Ignition status"
    3 "Data Invalid";

    0 "Awning may move"
    1 "Awning will not move because of Low Voltage status"
    3 "Data Invalid";

    0 "Awning may move"
    1 "Awning will not move because of generic lockout signal status"
    3 "Data Invalid";

    0 "Integrated awning light off, if present"
    1 "Integrated awning light on"
    3 "Data Invalid";

    0 "Secondary awning light off, if present"
    1 "Secondary awning light on"
    3 "Data Invalid";

    0 "No auto retraction based on park brake"
    1 "Awning set to automatically retract with park brake released"
    3 "Data Invalid";

    0 "No auto retraction based on park brake"
    1 "Awning set to automatically retract with park brake released"
    3 "Data Invalid";

CM_ "1FDCD / 2583547136";
BO_ 2583547136 AWNING_STATUS_2: 8  Vector__XXX
    SG_ Instance:               0|8@1+  (1,0)   [0|255] ""  Vector__XXX
    SG_ Motion_Sensitivity:     8|8@1+  (0.5,0) [0|255] "%" Vector__XXX
    SG_ Calibration:            16|2@1+ (1,0)   [0|4]   ""  Vector__XXX

    255 "Data Invalid";

CM_ "1FFB9";
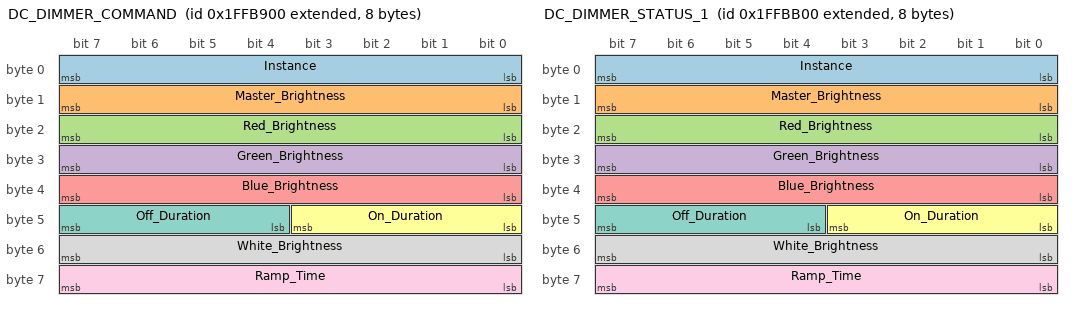
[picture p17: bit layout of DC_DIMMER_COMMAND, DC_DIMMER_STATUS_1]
BO_ 2181019904 DC_DIMMER_COMMAND: 8  Vector__XXX
    SG_ Instance:        0|8@1+  (1,0)   [0|255] ""    Vector__XXX
    SG_ Master_Brightness:        8|8@1+  (0.5,0)   [0|255] "%"    Vector__XXX
    SG_ Red_Brightness:        16|8@1+  (0.5,0)   [0|255] "%"    Vector__XXX
    SG_ Green_Brightness:        24|8@1+  (0.5,0)   [0|255] "%"    Vector__XXX
    SG_ Blue_Brightness:        32|8@1+  (0.5,0)   [0|255] "%"    Vector__XXX
    SG_ On_Duration:        40|4@1+  (1,0)   [0|15] "sec"    Vector__XXX
    SG_ Off_Duration:        44|4@1+  (1,0)   [0|15] "sec"    Vector__XXX
    SG_ White_Brightness:        48|8@1+  (0.5,0)   [0|255] "%"    Vector__XXX
    SG_ Ramp_Time:        56|8@1+  (0.1,0)   [0|255] "sec"    Vector__XXX

    255 "Data Invalid";

    255 "Data Invalid";

    255 "Data Invalid";

    255 "Data Invalid";

    0 "Always on"
    15 "Data Invalid";

    0 "One Shot” - Switch shall activate once, then stay off"
    15 "Data Invalid";

    255 "Data Invalid";

    255 "Data Invalid";

CM_ "1FFBB";
BO_ 2181020416 DC_DIMMER_STATUS_1: 8  Vector__XXX
    SG_ Instance:        0|8@1+  (1,0)   [0|255] ""    Vector__XXX
    SG_ Master_Brightness:        8|8@1+  (0.5,0)   [0|255] "%"    Vector__XXX
    SG_ Red_Brightness:        16|8@1+  (0.5,0)   [0|255] "%"    Vector__XXX
    SG_ Green_Brightness:        24|8@1+  (0.5,0)   [0|255] "%"    Vector__XXX
    SG_ Blue_Brightness:        32|8@1+  (0.5,0)   [0|255] "%"    Vector__XXX
    SG_ On_Duration:        40|4@1+  (1,0)   [0|15] "sec"    Vector__XXX
    SG_ Off_Duration:        44|4@1+  (1,0)   [0|15] "sec"    Vector__XXX
    SG_ White_Brightness:        48|8@1+  (0.5,0)   [0|255] "%"    Vector__XXX
    SG_ Ramp_Time:        56|8@1+  (0.1,0)   [0|255] "sec"    Vector__XXX

    255 "Data Invalid";

    255 "Data Invalid";

    255 "Data Invalid";

    255 "Data Invalid";

    0 "Always on"
    15 "Data Invalid";

    0 "One Shot” - Switch shall activate once, then stay off"
    15 "Data Invalid";

    255 "Data Invalid";

    255 "Data Invalid";

CM_ "1FEDA";
BO_ 2180962816 DC_DIMMER_STATUS_3: 8  Vector__XXX
    SG_ Instance:        0|8@1+  (1,0)   [0|255] ""    Vector__XXX
    SG_ Group:        8|8@1+  (1,0)   [0|255] ""    Vector__XXX
    SG_ Operating_Status:        16|8@1+  (0.5,0)   [0|255] "%"    Vector__XXX
    SG_ Last_Command:        40|8@1+  (1,0)   [0|255] ""    Vector__XXX

    251 "Value Is Changing"
    252 "Output Is Flashing"
    255 "Data Invalid";

    0 "Set Brightness"
    1 "ON"
    2 "ON Delay"
    3 "OFF";

CM_ "1FFEE";
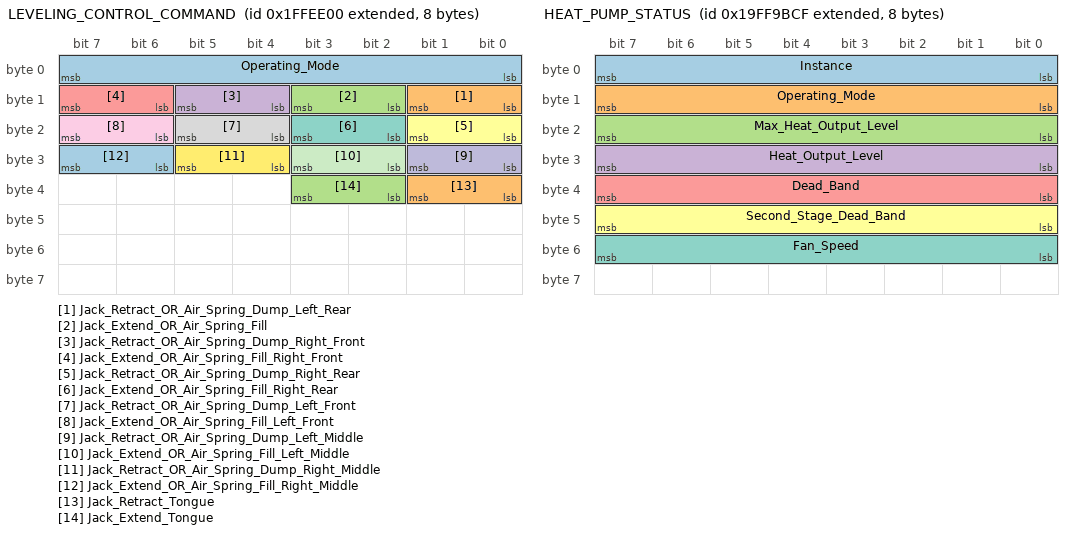
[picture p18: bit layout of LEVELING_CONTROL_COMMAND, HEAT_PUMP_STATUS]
BO_ 2181033472 LEVELING_CONTROL_COMMAND: 8  Vector__XXX
    SG_ Operating_Mode:        0|8@1+  (1,0)   [0|255] ""    Vector__XXX
    SG_ Jack_Retract_OR_Air_Spring_Dump_Left_Rear:        8|2@1+  (1,0)   [0|3] ""    Vector__XXX
    SG_ Jack_Extend_OR_Air_Spring_Fill:        10|2@1+  (1,0)   [0|3] ""    Vector__XXX
    SG_ Jack_Retract_OR_Air_Spring_Dump_Right_Front:        12|2@1+  (1,0)   [0|3] ""    Vector__XXX
    SG_ Jack_Extend_OR_Air_Spring_Fill_Right_Front:        14|2@1+  (1,0)   [0|3] ""    Vector__XXX
    SG_ Jack_Retract_OR_Air_Spring_Dump_Right_Rear:        16|2@1+  (1,0)   [0|3] ""    Vector__XXX
    SG_ Jack_Extend_OR_Air_Spring_Fill_Right_Rear:        18|2@1+  (1,0)   [0|3] ""    Vector__XXX
    SG_ Jack_Retract_OR_Air_Spring_Dump_Left_Front:        20|2@1+  (1,0)   [0|3] ""    Vector__XXX
    SG_ Jack_Extend_OR_Air_Spring_Fill_Left_Front:        22|2@1+  (1,0)   [0|3] ""    Vector__XXX
    SG_ Jack_Retract_OR_Air_Spring_Dump_Left_Middle:        24|2@1+  (1,0)   [0|3] ""    Vector__XXX
    SG_ Jack_Extend_OR_Air_Spring_Fill_Left_Middle:        26|2@1+  (1,0)   [0|3] ""    Vector__XXX
    SG_ Jack_Retract_OR_Air_Spring_Dump_Right_Middle:        28|2@1+  (1,0)   [0|3] ""    Vector__XXX
    SG_ Jack_Extend_OR_Air_Spring_Fill_Right_Middle:        30|2@1+  (1,0)   [0|3] ""    Vector__XXX
    SG_ Jack_Retract_Tongue:        32|2@1+  (1,0)   [0|3] ""    Vector__XXX
    SG_ Jack_Extend_Tongue:        34|2@1+  (1,0)   [0|3] ""    Vector__XXX

    0 "Inactive"
    1 "Suspension raise (all air springs) active"
    2 "Suspension dump (all air springs) active"
    3 "Store active (store jacks/go to ride height)"
    4 "Manual air leveling (Deprecated in favor of 41-44)"
    5 "Automatic air leveling started"
    6 "Start deploy kick-down jacks"
    7 "Manual hydraulic leveling (Deprecated in favor of 71-74)"
    8 "Automatic hydraulic/electric leveling started"
    9 "Kneel started (dump front air springs only)"
    10 "Auto hitch height"
    11 "Abort Function"
    34 "Jack calibration mode"
    41 "Manual air leveling - Four point"
    42 "Manual air leveling - Biax mode"
    43 "Manual air leveling - 3 point mode"
    44 "Manual air leveling - Multi point mode 5+"
    51 "Automatic air leveling – Four point"
    52 "Automatic air leveling – Biax mode"
    53 "Automatic air leveling – 3 point mode"
    54 "Automatic air leveling - Multi point mode 5+"
    71 "Manual hydraulic/electric leveling - Four point"
    72 "Manual hydraulic/electric leveling - Biax mode"
    73 "Manual hydraulic/electric leveling - 3 point mode"
    74 "Manual hydraulic leveling - Multi point mode 5+"
    81 "Automatic hydraulic leveling – Four point"
    82 "Automatic hydraulic leveling – Biax mode"
    83 "Automatic hydraulic leveling – 3 point mode"
    84 "Automatic hydraulic leveling - Multi point mode 5+"
    99 "Clear Jack error"
    255 "Data Invalid";

    0 "Off"
    1 "On"
    3 "Data Invalid";

    0 "Off"
    1 "On"
    3 "Data Invalid";

    0 "Off"
    1 "On"
    3 "Data Invalid";

    0 "Off"
    1 "On"
    3 "Data Invalid";

    0 "Off"
    1 "On"
    3 "Data Invalid";

    0 "Off"
    1 "On"
    3 "Data Invalid";

    0 "Off"
    1 "On"
    3 "Data Invalid";

    0 "Off"
    1 "On"
    3 "Data Invalid";

    0 "Off"
    1 "On"
    3 "Data Invalid";

    0 "Off"
    1 "On"
    3 "Data Invalid";

    0 "Off"
    1 "On"
    3 "Data Invalid";

    0 "Off"
    1 "On"
    3 "Data Invalid";

    0 "Off"
    1 "On"
    3 "Data Invalid";

    0 "Off"
    1 "On"
    3 "Data Invalid";

CM_ "1FFEC";
BO_ 2181032960 LEVELING_JACK_STATUS: 8  Vector__XXX
    SG_ Jack_Type:        0|4@1+  (1,0)   [0|15] ""    Vector__XXX
    SG_ Number_Of_Jacks:        4|4@1+  (1,0)   [0|15] ""    Vector__XXX
    SG_ Extension_Left_Rear:        8|2@1+  (1,0)   [0|3] ""    Vector__XXX
    SG_ Extension_Right_Front:        10|2@1+  (1,0)   [0|3] ""    Vector__XXX
    SG_ Extension_Right_Rear:        12|2@1+  (1,0)   [0|3] ""    Vector__XXX
    SG_ Extension_Left_Front:        14|2@1+  (1,0)   [0|3] ""    Vector__XXX
    SG_ Extension_Auxiliary_Jack_1:        16|2@1+  (1,0)   [0|3] ""    Vector__XXX
    SG_ Extension_Auxiliary_Jack_2:        18|2@1+  (1,0)   [0|3] ""    Vector__XXX
    SG_ Extension_Auxiliary_Jack_3:        20|2@1+  (1,0)   [0|3] ""    Vector__XXX
    SG_ Extension_Auxiliary_Jack_4:        22|2@1+  (1,0)   [0|3] ""    Vector__XXX
    SG_ Stability_Left_Rear:        24|2@1+  (1,0)   [0|3] ""    Vector__XXX
    SG_ Stability_Right_Front:        26|2@1+  (1,0)   [0|3] ""    Vector__XXX
    SG_ Stability_Right_Rear:        28|2@1+  (1,0)   [0|3] ""    Vector__XXX
    SG_ Stability_Left_Front:        30|2@1+  (1,0)   [0|3] ""    Vector__XXX
    SG_ Stability_Auxiliary_Jack_1:        32|2@1+  (1,0)   [0|3] ""    Vector__XXX
    SG_ Stability_Auxiliary_Jack_2:        34|2@1+  (1,0)   [0|3] ""    Vector__XXX
    SG_ Stability_Auxiliary_Jack_3:        36|2@1+  (1,0)   [0|3] ""    Vector__XXX
    SG_ Stability_Auxiliary_Jack_4:        38|2@1+  (1,0)   [0|3] ""    Vector__XXX

    0 "Straight Acting"
    1 "Kick-Down"
    15 "Data Invalid";

    0 "No Action"
    1 "Jack is Extended. Coach is not safe to move"
    3 "Data Invalid";

    0 "No Action"
    1 "Jack is Extended. Coach is not safe to move"
    3 "Data Invalid";

    0 "No Action"
    1 "Jack is Extended. Coach is not safe to move"
    3 "Data Invalid";

    0 "No Action"
    1 "Jack is Extended. Coach is not safe to move"
    3 "Data Invalid";

    0 "No Action"
    1 "Jack is Extended. Coach is not safe to move"
    3 "Data Invalid";

    0 "No Action"
    1 "Jack is Extended. Coach is not safe to move"
    3 "Data Invalid";

    0 "No Action"
    1 "Jack is Extended. Coach is not safe to move"
    3 "Data Invalid";

    0 "No Action"
    1 "Jack is Extended. Coach is not safe to move"
    3 "Data Invalid";

    0 "No Action"
    1 "Pressure detected. Jack is bearing weight on the ground"
    3 "Data Invalid";

    0 "No Action"
    1 "Pressure detected. Jack is bearing weight on the ground"
    3 "Data Invalid";

    0 "No Action"
    1 "Pressure detected. Jack is bearing weight on the ground"
    3 "Data Invalid";

    0 "No Action"
    1 "Pressure detected. Jack is bearing weight on the ground"
    3 "Data Invalid";

    0 "No Action"
    1 "Pressure detected. Jack is bearing weight on the ground"
    3 "Data Invalid";

    0 "No Action"
    1 "Pressure detected. Jack is bearing weight on the ground"
    3 "Data Invalid";

    0 "No Action"
    1 "Pressure detected. Jack is bearing weight on the ground"
    3 "Data Invalid";

    0 "No Action"
    1 "Pressure detected. Jack is bearing weight on the ground"
    3 "Data Invalid";

CM_ "1FFD4";
BO_ 2181026816 INVERTER_STATUS: 8  Vector__XXX
    SG_ Instance:        0|8@1+  (1,0)   [0|255] ""    Vector__XXX
    SG_ Status:        8|8@1+  (1,0)   [0|255] ""    Vector__XXX
    SG_ Battery_Temperature_Sensor_Present:        16|2@1+  (1,0)   [0|3] ""    Vector__XXX
    SG_ Load_Sense_Enabled:        18|2@1+  (1,0)   [0|3] ""    Vector__XXX

    0 "Disabled"
    1 "Invert"
    2 "AC passthru"
    3 "APS Only"
    4 "Load sense (Unit is waiting for a load.)"
    5 "Waiting to Invert"
    255 "Data invalid";

    0 "No battery temperature sensor in use"
    1 "Sensor is present and active"
    3 "Data Invalid";

    0 "Load sense disabled"
    1 "Load sense enabled"
    3 "Data Invalid";

CM_ "1FF9B";
BO_ 2583665615 HEAT_PUMP_STATUS: 8  Vector__XXX
    SG_ Instance:        0|8@1+  (1,0)   [0|255] ""    Vector__XXX
    SG_ Operating_Mode:        8|8@1+  (1,0)   [0|255] ""    Vector__XXX
    SG_ Max_Heat_Output_Level:        16|8@1+  (0.5,0)   [0|255] "%"    Vector__XXX
    SG_ Heat_Output_Level:        24|8@1+  (0.5,0)   [0|255] "%"    Vector__XXX
    SG_ Dead_Band:        32|8@1+  (0.1,0)   [0|255] "deg C"    Vector__XXX
    SG_ Second_Stage_Dead_Band:        40|8@1+  (0.1,0)   [0|255] "%"    Vector__XXX
    SG_ Fan_Speed:        48|8@1+  (0.5,0) [0|255] "%"    Vector__XXX

    0 "Automatic"
    1 "Manual"
    255 "Data Invalid";

CM_ "1FF9A";
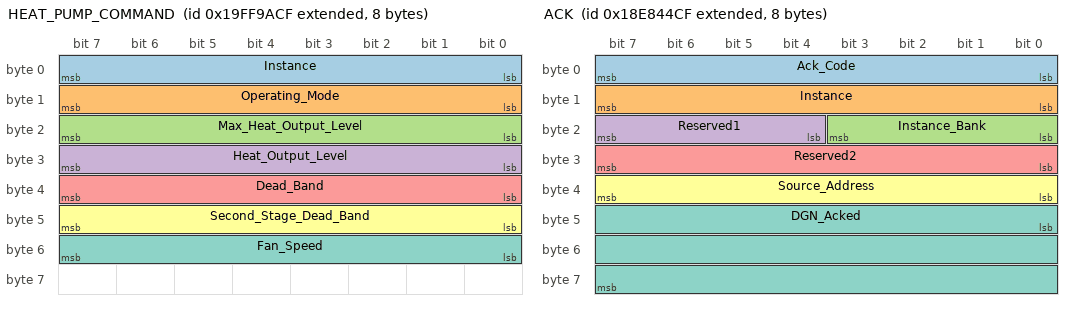
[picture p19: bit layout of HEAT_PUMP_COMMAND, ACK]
BO_ 2583665359 HEAT_PUMP_COMMAND: 8  Vector__XXX
    SG_ Instance:        0|8@1+  (1,0)   [0|255] ""    Vector__XXX
    SG_ Operating_Mode:        8|8@1+  (1,0)   [0|255] ""    Vector__XXX
    SG_ Max_Heat_Output_Level:        16|8@1+  (0.5,0)   [0|255] "%"    Vector__XXX
    SG_ Heat_Output_Level:        24|8@1+  (0.5,0)   [0|255] "%"    Vector__XXX
    SG_ Dead_Band:        32|8@1+  (0.1,0)   [0|255] "deg C"    Vector__XXX
    SG_ Second_Stage_Dead_Band:        40|8@1+  (0.1,0)   [0|255] "%"    Vector__XXX
    SG_ Fan_Speed:        48|8@1+  (0.5,0) [0|255] "%"    Vector__XXX

    0 "Automatic"
    1 "Manual"
    255 "Data Invalid";

CM_ "E844";
BO_ 2565358799 ACK: 8  Vector__XXX
    SG_ Ack_Code:        0|8@1+  (1,0)   [0|255] ""    Vector__XXX
    SG_ Instance:        8|8@1+  (1,0)   [0|255] ""    Vector__XXX
    SG_ Instance_Bank:        16|4@1+  (1,0)   [0|255] ""    Vector__XXX
    SG_ Reserved1:        20|4@1+  (1,0)   [0|255] ""    Vector__XXX
    SG_ Reserved2:        24|8@1+  (1,0)   [0|255] ""    Vector__XXX
    SG_ Source_Address:  32|8@1+  (1,0)   [0|255] ""    Vector__XXX
    SG_ DGN_Acked:        40|24@1+  (1,0) [0|255] ""    Vector__XXX

    0 "ACK"
    1 "NACK"
    2 "Command is not acceptable from the source."
    3 "Conditions do not allow command to be executed."
    4 "Command is not formatted properly."
    5 "Command parameters are out of range."
    6 "Command requires a security password."
    7 "Command requires more time to execute. This should be followed by an ACK when complete.
Command overridden by"
    8 "Command overridden by user."
    255 " Data Invalid";

CM_ "EA44 - HMI addressed or other controllers on 0x44 SA";
BO_ 2565489664 REQUEST_FOR_DGN: 8   Vector__XXX
    SG_ Desired_DGN:    0|24@1+ (1,0)   [0|16777216]    ""  Vector__XXX
    SG_ Instance:   24|8@1+ (1,0)   [0|255] ""  Vector__XXX
    SG_ Instance_Bank:   32|8@1+ (1,0)   [0|255] ""  Vector__XXX
